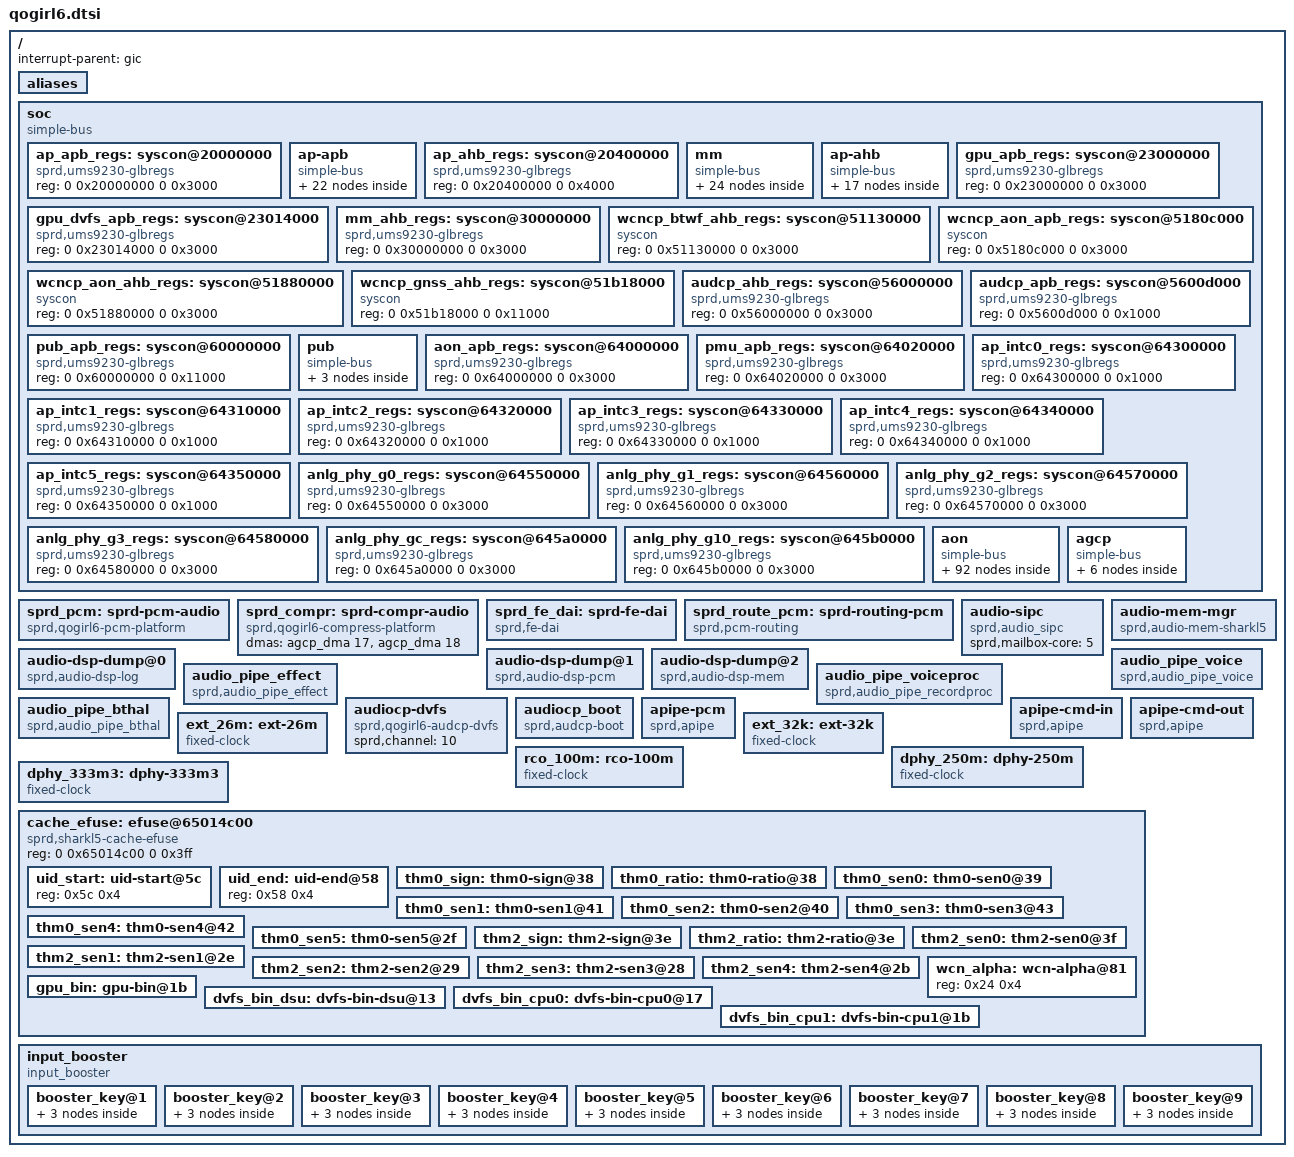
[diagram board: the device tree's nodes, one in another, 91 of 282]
// SPDX-License-Identifier: GPL-2.0-only
/*
 * Unisoc Qogirl6 platform DTS file
 *
 * Copyright (C) 2020, Unisoc Inc.
 */

#include <dt-bindings/clock/sprd,ums9230-clk.h>
#include <dt-bindings/soc/sprd,qogirl6-regs.h>
#include <dt-bindings/soc/sprd,qogirl6-mask.h>
#include <dt-bindings/debug/busmonitor/busmonitor.h>
#include <dt-bindings/debug/dmc_mpu/qogirl6_dmc_mpu.h>

/ {
	interrupt-parent = <&gic>;
	#address-cells = <2>;
	#size-cells = <2>;

	aliases {
		i2c0 = &i2c0;
		i2c1 = &i2c1;
		i2c2 = &i2c2;
		i2c3 = &i2c3;
		i2c4 = &i2c4;
		i2c5 = &i2c5;
		i2c6 = &i2c6;
		i2c7 = &aon_i2c0;
		spi0 = &spi0;
		spi1 = &spi1;
		spi2 = &spi2;
		spi3 = &spi3;
		spi4 = &adi_bus;
		thm-sensor15 = &cluster0_sensor;
		thm-sensor16 = &cluster1_sensor;
		thm-sensor17 = &soc_sensor;
	};

	soc: soc {
		compatible = "simple-bus";
		#address-cells = <2>;
		#size-cells = <2>;
		ranges;

		ap_apb_regs: syscon@20000000 {
			compatible = "sprd,ums9230-glbregs", "syscon";
			#syscon-cells = <2>;
			reg = <0 0x20000000 0 0x3000>;
		};

		ap-apb {
			compatible = "simple-bus";
			#address-cells = <2>;
			#size-cells = <2>;
			ranges;

			uart0: serial@0x200a0000  {
				compatible = "sprd,ums9230-uart",
					     "sprd,sc9836-uart";
				reg = <0 0x200a0000 0 0x100>;
				interrupts = <GIC_SPI 2 IRQ_TYPE_LEVEL_HIGH>;
				clock-names = "enable", "uart", "source";
				clocks = <&apapb_gate CLK_UART0_EB>,
					<&ap_clk CLK_AP_UART0>, <&ext_26m>;
				status = "disabled";
			};

			uart1: serial@0x200b0000 {
				compatible = "sprd,ums9230-uart",
					     "sprd,sc9836-uart";
				reg = <0 0x200b0000 0 0x100>;
				interrupts = <GIC_SPI 3 IRQ_TYPE_LEVEL_HIGH>;
				clock-names = "enable", "uart", "source";
				clocks = <&apapb_gate CLK_UART1_EB>,
					<&ap_clk CLK_AP_UART1>, <&ext_26m>;
				status = "disabled";
			};

			uart2: serial@0x200c0000 {
				compatible = "sprd,ums9230-uart",
						"sprd,sc9836-uart";
				reg = <0 0x200c0000 0 0x100>;
				interrupts = <GIC_SPI 4 IRQ_TYPE_LEVEL_HIGH>;
				clock-names = "enable", "uart", "source";
				clocks = <&apapb_gate CLK_UART2_EB>,
					<&ap_clk CLK_AP_UART2>, <&ext_26m>;
				status = "disabled";
			};

			i2c0: i2c@0x200d0000 {
				compatible = "sprd,qogirl6-i2c";
				reg = <0 0x200d0000 0 0x100>;
				interrupts = <GIC_SPI 11 IRQ_TYPE_LEVEL_HIGH>;
				clock-frequency = <400000>;
				#address-cells = <1>;
				#size-cells = <0>;
				status = "disabled";
				syscon-names = "i2c_rst";
				syscons =
					<&ap_apb_regs REG_AP_APB_APB_RST MASK_AP_APB_I2C0_SOFT_RST>;
			};

			i2c1: i2c@0x200e0000 {
				compatible = "sprd,qogirl6-i2c";
				reg = <0 0x200e0000 0 0x100>;
				interrupts = <GIC_SPI 12 IRQ_TYPE_LEVEL_HIGH>;
				clock-frequency = <400000>;
				#address-cells = <1>;
				#size-cells = <0>;
				status = "disabled";
				syscon-names = "i2c_rst";
				syscons =
					<&ap_apb_regs REG_AP_APB_APB_RST MASK_AP_APB_I2C1_SOFT_RST>;
			};

			i2c2: i2c@0x200f0000 {
				compatible = "sprd,qogirl6-i2c";
				reg = <0 0x200f0000 0 0x100>;
				interrupts = <GIC_SPI 13 IRQ_TYPE_LEVEL_HIGH>;
				clock-frequency = <400000>;
				#address-cells = <1>;
				#size-cells = <0>;
				status = "disabled";
				syscon-names = "i2c_rst";
				syscons =
					<&ap_apb_regs REG_AP_APB_APB_RST MASK_AP_APB_I2C2_SOFT_RST>;
			};

			i2c3: i2c@0x20100000 {
				compatible = "sprd,qogirl6-i2c";
				reg = <0 0x20100000 0 0x100>;
				interrupts = <GIC_SPI 14 IRQ_TYPE_LEVEL_HIGH>;
				clock-frequency = <400000>;
				#address-cells = <1>;
				#size-cells = <0>;
				status = "disabled";
				syscon-names = "i2c_rst";
				syscons =
					<&ap_apb_regs REG_AP_APB_APB_RST MASK_AP_APB_I2C3_SOFT_RST>;
			};

			i2c4: i2c@0x20110000 {
				compatible = "sprd,qogirl6-i2c";
				reg = <0 0x20110000 0 0x100>;
				interrupts = <GIC_SPI 15 IRQ_TYPE_LEVEL_HIGH>;
				clock-frequency = <400000>;
				#address-cells = <1>;
				#size-cells = <0>;
				status = "disabled";
				syscon-names = "i2c_rst";
				syscons =
					<&ap_apb_regs REG_AP_APB_APB_RST MASK_AP_APB_I2C4_SOFT_RST>;
			};

			i2s0: i2s@0x20160000 {
				compatible = "sprd,i2s";
				reg = <0 0x20160000 0 0x1000>;
				sprd,dai_name = "i2s_bt_sco0";
				sprd,hw_port = <0>;
				sprd,syscon-ap-apb = <&ap_apb_regs>;
				#sound-dai-cells = <0>;
				status = "disable";
				clock-names = "clk_iis0";
				clocks = <&ap_clk CLK_AP_IIS0>;
			};

			i2c5: i2c@0x20210000 {
				compatible = "sprd,qogirl6-i2c";
				reg = <0 0x20210000 0 0x100>;
				interrupts = <GIC_SPI 35 IRQ_TYPE_LEVEL_HIGH>;
				clock-frequency = <400000>;
				#address-cells = <1>;
				#size-cells = <0>;
				status = "disabled";
				syscon-names = "i2c_rst";
				syscons =
					<&ap_apb_regs REG_AP_APB_APB_RST MASK_AP_APB_I2C5_SOFT_RST>;
			};

			i2c6: i2c@0x20220000 {
				compatible = "sprd,qogirl6-i2c";
				reg = <0 0x20220000 0 0x100>;
				interrupts = <GIC_SPI 36 IRQ_TYPE_LEVEL_HIGH>;
				clock-frequency = <400000>;
				#address-cells = <1>;
				#size-cells = <0>;
				status = "disabled";
				syscon-names = "i2c_rst";
				syscons =
					<&ap_apb_regs REG_AP_APB_APB_RST MASK_AP_APB_I2C6_SOFT_RST>;
			};

			spi0: spi@20120000{
				compatible = "sprd,sc9860-spi", "sprd,sharkl5-spi";
				reg = <0 0x20120000 0 0x1000>;
				interrupts = <GIC_SPI 5 IRQ_TYPE_LEVEL_HIGH>;
				#address-cells = <1>;
				#size-cells = <0>;
				status = "disabled";
			};

			spi1: spi@20130000{
				compatible = "sprd,sc9860-spi", "sprd,sharkl5-spi";
				reg = <0 0x20130000 0 0x1000>;
				interrupts = <GIC_SPI 6 IRQ_TYPE_LEVEL_HIGH>;
				#address-cells = <1>;
				#size-cells = <0>;
				status = "disabled";
			};

			spi2: spi@20140000{
				compatible = "sprd,sc9860-spi", "sprd,sharkl5-spi";
				reg = <0 0x20140000 0 0x1000>;
				interrupts = <GIC_SPI 7 IRQ_TYPE_LEVEL_HIGH>;
				#address-cells = <1>;
				#size-cells = <0>;
				status = "disabled";
			};

			spi3: spi@20150000{
				compatible = "sprd,sc9860-spi", "sprd,sharkl5-spi";
				reg = <0 0x20150000 0 0x1000>;
				interrupts = <GIC_SPI 8 IRQ_TYPE_LEVEL_HIGH>;
				#address-cells = <1>;
				#size-cells = <0>;
				status = "disabled";
			};

			sdio3: sdio@201d0000 {
				compatible = "sprd,sdhc-r11p1";
				reg = <0 0x201d0000 0 0x1000>;
				interrupts = <GIC_SPI 10 IRQ_TYPE_LEVEL_HIGH>;
				status = "disabled";
			};

			sdio0: sdio@201a0000 {
				compatible = "sprd,sdhc-r11p1";
				reg = <0 0x201a0000 0 0x1000>;
				interrupts = <GIC_SPI 19 IRQ_TYPE_LEVEL_HIGH>;
				status = "disabled";
				syscons = <&aon_apb_regs REG_AON_APB_AP_SDIO0_PHY_CTRL MASK_AON_APB_AP_SDIO0_CARD_PRESENT_32K>,
					  <&aon_apb_regs REG_AON_APB_AP_SDIO0_PHY_CTRL MASK_AON_APB_AP_SDIO0_CARD_PROTECT_32K>,
					  <&aon_apb_regs REG_AON_APB_AP_SDIO0_PHY_CTRL MASK_AON_APB_AP_SDIO0_CARDDET_DBNC_EN_32K>,
					  <&aon_apb_regs REG_AON_APB_AP_SDIO0_PHY_CTRL MASK_AON_APB_AP_SDIO0_CARDDET_DBNC_THD_32K>;
				syscon-names = "sd_detect_pol",
					       "sd_hotplug_protect_en",
					       "sd_hotplug_debounce_en",
					       "sd_hotplug_debounce_cn";
			};

			sdio1: sdio@201b0000 {
				compatible = "sprd,sdhc-r11p1";
				reg = <0 0x201b0000 0 0x1000>;
				interrupts = <GIC_SPI 20 IRQ_TYPE_LEVEL_HIGH>;
				status = "disabled";
			};

			sdio2: sdio@201c0000 {
				compatible = "sprd,sdhc-r11p1";
				reg = <0 0x201c0000 0 0x1000>;
				interrupts = <GIC_SPI 21 IRQ_TYPE_LEVEL_HIGH>;
				status = "disabled";
			};

			apsys_dvfs: apsys-dvfs@71700000 {
				compatible = "sprd,hwdvfs-apsys-qogirl6";
				reg = <0x0 0x20014000 0x0 0x15c>;

				sprd,ap-dvfs-up-window = <0x40>;
				sprd,ap-dvfs-down-window = <0x80>;
			};

			crypto_engine_rng: rng@201e0000 {
				compatible = "sprd,sprd-trng";
				reg = <0x0 0x201e0000 0x0 0x10000>;
				clock-names = "ce-pub-eb", "ap-ce-clk",
							  "source";
				clocks = <&apapb_gate CLK_CE_PUB_EB>,
						 <&ap_clk CLK_AP_CE>,
						 <&pll1 CLK_TWPLL_256M>;
			};

			ufs: ufs@20200000 {
				compatible  = "sprd,ufshc";
				vcc-supply = <&vddemmccore>;
				vcc-fixed-regulator;
				clock-names = "ufs_reg_eb", "ufs_en",
					      "ufs_pclk", "ufs_pclk_source",
					      "ufs_hclk", "ufs_hclk_source";
				clocks = <&apapb_gate CLK_UFS_REG_EB>,
					 <&apapb_gate CLK_UFS_EB>,
					 <&ap_clk CLK_UFS_PCK>,
					 <&pll1 CLK_TWPLL_256M>,
					 <&ap_clk CLK_UFS_HCK>,
					 <&pll1 CLK_TWPLL_256M>;
				freq-table-hz = <0 0>,
						<0 0>,
						<0 0>,
						<0 0>,
						<0 0>,
						<0 0>;
				/*#clock-cells = <1>;*/
				reg = <0 0x20200000 0 0x10000>,
				      <0 0x20400000 0 0x10000>,
				      <0 0x64560000 0 0x10000>;
				reg-names = "ufshci_reg",
					    "ap_ahb_reg",
					    "ufs_analog_reg";
				syscons =
					<&aon_apb_regs REG_AON_APB_APB_EB1 (MASK_AON_APB_PIN_EB | MASK_AON_APB_ANA_EB)>,
					<&ap_ahb_regs REG_AP_AHB_UFS_CLK_CTRL MASK_AP_AHB_CG_CFGCLK_SW>,
					<&ap_apb_regs REG_AP_APB_APB_RST MASK_AP_APB_UFS_REG_SOFT_RST>,
					<&ap_apb_regs REG_AP_APB_APB_EB1 MASK_AP_APB_UFS_EB>,
					<&ap_ahb_regs REG_AP_AHB_MPHY_CB_CHANNEL_0 MASK_AP_AHB_REFCLKON>,
					<&ap_ahb_regs REG_AP_AHB_UFS_LP_CTRL_1 (MASK_AP_AHB_UFS_FORCE_LP_RESET_N |
								MASK_AP_AHB_UFS_FORCE_LP_PWR_READY | MASK_AP_AHB_UFS_SEL_LP_PWR_READY |
								MASK_AP_AHB_UFS_SEL_LP_RESET_N | MASK_AP_AHB_UFS_SEL_LP_ISOL_EN )>,
					<&ap_ahb_regs REG_AP_AHB_UFS_LP_CTRL_1 MASK_AP_AHB_UFS_FORCE_LP_ISOL_EN>,
					<&ap_ahb_regs REG_AP_AHB_UFS_LP_CTRL_1 (MASK_AP_AHB_UFS_CG_LP_PWR_READY_BYPASS | MASK_AP_AHB_UFS_FORCE_LP_RESET_N)>,
					<&ap_ahb_regs REG_AP_AHB_MPHY_CB_CHANNEL_0 (MASK_AP_AHB_CB_RESET | MASK_AP_AHB_CB_CFGCLK)>;
				syscon-names =
					"aon_apb_ufs_en",
					"ap_ahb_ufs_clk",
					"ap_apb_ufs_rst",
					"ap_apb_ufs_en",
					"ufs_refclk_on",
					"ahb_ufs_lp",
					"ahb_ufs_force_isol",
					"ahb_ufs_lp_1",
					"ahb_ufs_cb";
				interrupts = <GIC_SPI 147 IRQ_TYPE_LEVEL_HIGH>;
			};
		};

		ap_ahb_regs: syscon@20400000 {
			compatible = "sprd,ums9230-glbregs", "syscon";
			#syscon-cells = <2>;
			reg = <0 0x20400000 0 0x4000>;
		};

		mm {
			compatible = "simple-bus";
			#address-cells = <2>;
			#size-cells = <2>;
			ranges;

			mm_domain: mm_domain {
				compatible = "sprd,mm-domain";

				syscon-names = "force_shutdown",
						"shutdown_en",
						"power_state",
						"aon_apb_mm_eb";
				syscons = <&pmu_apb_regs
					REG_PMU_APB_PD_MM_CFG_0
					MASK_PMU_APB_PD_MM_FORCE_SHUTDOWN>,
					<&pmu_apb_regs
					REG_PMU_APB_PD_MM_CFG_0
					MASK_PMU_APB_PD_MM_AUTO_SHUTDOWN_EN>,
					<&pmu_apb_regs
					REG_PMU_APB_PWR_STATUS_DBG_6
					MASK_PMU_APB_PD_MM_STATE>,
					<&aon_apb_regs
					REG_AON_APB_APB_EB0
					MASK_AON_APB_MM_EB>;

				clock-names = "clk_mm_eb",
					"clk_mm_ahb_eb",
					"clk_mm_ahb",
					"clk_mm_ahb_parent",
					"clk_mm_mtx",
					"clk_mm_mtx_parent",
					"clk_isppll";
				clocks = <&aonapb_gate CLK_MM_EB>,
					<&mm_gate CLK_MM_CKG_EB>,
					<&mm_clk CLK_MM_AHB>,
					<&pll1 CLK_TWPLL_153M6>,
					<&mm_clk CLK_MM_MTX>,
					<&pll1 CLK_TWPLL_512M>,
					<&pll1 CLK_ISPPLL_468M>;
				mm_qos_threshold = <&mm_qos_threshold>;
			};

			vsp: video-codec@32000000 {
				compatible = "sprd,qogirl6-vsp";
				reg = <0 0x32000000 0 0xc000>;
				interrupts = <GIC_SPI 34 IRQ_TYPE_LEVEL_HIGH>;

				syscons =
					<&ap_ahb_regs REG_AP_AHB_AHB_RST
					(MASK_AP_AHB_VSP_SOFT_RST |
					MASK_AP_AHB_VSP_GLOBAL_SOFT_RST)>,
					<&pmu_apb_regs
					REG_PMU_APB_PD_AP_VSP_CFG_0
					MASK_PMU_APB_PD_AP_VSP_FORCE_SHUTDOWN>,
					<&pmu_apb_regs
					REG_PMU_APB_PD_AP_VSP_CFG_0
					MASK_PMU_APB_PD_AP_VSP_AUTO_SHUTDOWN_EN>,
					<&pmu_apb_regs
					REG_PMU_APB_PWR_STATUS_DBG_9
					MASK_PMU_APB_PD_AP_VSP_STATE>,
					<&aon_apb_regs
					REG_AON_APB_APB_EB1
					MASK_AON_APB_AP_SYST_EB>;
				syscon-names = "reset",
					"pmu_vsp_force_shutdown",
					"pmu_vsp_auto_shutdown",
					"pmu_pwr_status",
					"vsp_domain_eb";

				iommus = <&iommu_vsp>;
				status = "okay";
			};

			iommu_vsp: iommu@32000000 {
				compatible = "sprd,iommuvau-vsp";
				reg = <0x0 0x32000000 0x0 0x80>;
				sprd,iova-base = <0x20000000>;
				sprd,iova-size = <0x10000000>;
				reg_name = "mmu_reg";
				status = "disable";
				#iommu-cells = <0>;
			};

			jpg: jpg-codec@36000000{
				compatible = "sprd,qogirl6-jpg";
				reg = <0 0x36000000 0 0xc000>;
				interrupts = <GIC_SPI 42 IRQ_TYPE_LEVEL_HIGH>;

				syscons = <&mm_ahb_regs REG_MM_AHB_AHB_RST
					MASK_MM_AHB_JPG_SOFT_RST_MASK>,
					<&aon_apb_regs
					REG_AON_APB_APB_EB0
					MASK_AON_APB_MM_EB>;
				syscon-names = "reset",
					"aon_apb_eb";
					iommus = <&iommu_jpg>;
					jpg_qos = <&jpg_qos>;
				status = "disabled";
			};

			iommu_jpg: iommu@36000300 {
				compatible = "sprd,iommuvau-jpg";
				reg = <0x0 0x36000300 0x0 0x80>;
				sprd,iova-base = <0x60000000>;
				sprd,iova-size = <0x10000000>;
				reg_name = "mmu_reg";
				status = "disabled";
				#iommu-cells = <0>;
			};

			mipi_csi_phy0: mipi-csi-phy0 {
				compatible = "sprd,mipi-csi-phy";
				sprd,phyid = <0>;
				sprd,phyname = "4lane";
				status = "disabled";
			};

			mipi_csi_phy1: mipi-csi-phy1 {
				compatible = "sprd,mipi-csi-phy";
				sprd,phyid = <1>;
				sprd,phyname = "2p2";
				status = "disabled";
			};

			mipi_csi_phy1_m: mipi-csi-phy1-m {
				compatible = "sprd,mipi-csi-phy";
				sprd,phyid = <3>;
				sprd,phyname = "2p2_m";
				status = "disabled";
			};

			mipi_csi_phy1_s: mipi-csi-phy1-s {
				compatible = "sprd,mipi-csi-phy";
				sprd,phyid = <4>;
				sprd,phyname = "2p2_s";
				status = "disabled";
			};

			mipi_csi_phy2: mipi-csi-phy2 {
				compatible = "sprd,mipi-csi-phy";
				sprd,phyid = <2>;
				sprd,phyname = "2p2ro";
				status = "disabled";
			};
			mipi_csi_phy2_m: mipi-csi-phy2-m {
				compatible = "sprd,mipi-csi-phy";
				sprd,phyid = <5>;
				sprd,phyname = "2p2ro_m";
				status = "disabled";
			};

			mipi_csi_phy2_s: mipi-csi-phy2-s {
				compatible = "sprd,mipi-csi-phy";
				sprd,phyid = <6>;
				sprd,phyname = "2p2ro_s";
				status = "disabled";
			};
			csi0: csi00@3e200000 {
				compatible = "sprd,csi-controller";
				reg = <0 0x3e200000 0 0x1000>;
				interrupts = <GIC_SPI 45 IRQ_TYPE_LEVEL_HIGH>,
					<GIC_SPI 46 IRQ_TYPE_LEVEL_HIGH>,
					<GIC_SPI 47 IRQ_TYPE_LEVEL_HIGH>,
					<GIC_SPI 48 IRQ_TYPE_LEVEL_HIGH>;
				clock-names = "clk_mipi_csi_gate_eb",
					"clk_csi_eb",
					"mipi_csi_src_eb";
				clocks = <&mm_gate CLK_MM_MIPI_CSI0_EB>,
					<&mm_gate CLK_MM_CSI0_EB>,
					<&mm_clk CLK_MIPI_CSI0>;
				sprd,aon-apb-syscon = <&aon_apb_regs>;
				sprd,cam-ahb-syscon = <&mm_ahb_regs>;
				sprd,anlg_phy_g10_controller = <&anlg_phy_g10_regs>;
				sprd,csi-id = <0>;
				sprd,dcam-id = <0>;
				sprd,ip-version = <0x200>;
				status = "okay";
			};

			csi1: csi01@3e300000 {
				compatible = "sprd,csi-controller";
				reg = <0 0x3e300000 0 0x1000>;
				interrupts = <GIC_SPI 49 IRQ_TYPE_LEVEL_HIGH>,
					<GIC_SPI 50 IRQ_TYPE_LEVEL_HIGH>,
					<GIC_SPI 51 IRQ_TYPE_LEVEL_HIGH>,
					<GIC_SPI 52 IRQ_TYPE_LEVEL_HIGH>;
				clock-names = "clk_mipi_csi_gate_eb",
					"clk_csi_eb",
					"mipi_csi_src_eb";
				clocks = <&mm_gate CLK_MM_MIPI_CSI1_EB>,
					<&mm_gate CLK_MM_CSI1_EB>,
					<&mm_clk CLK_MIPI_CSI1>;
				sprd,aon-apb-syscon = <&aon_apb_regs>;
				sprd,cam-ahb-syscon = <&mm_ahb_regs>;
				sprd,anlg_phy_g10_controller = <&anlg_phy_g10_regs>;
				sprd,csi-id = <1>;
				sprd,dcam-id = <1>;
				sprd,ip-version = <0x200>;
				status = "okay";
			};

			csi2: csi02@3e400000 {
				compatible = "sprd,csi-controller";
				reg = <0 0x3e400000 0 0x1000>;
				interrupts = <GIC_SPI 53 IRQ_TYPE_LEVEL_HIGH>,
					<GIC_SPI 54 IRQ_TYPE_LEVEL_HIGH>,
					<GIC_SPI 55 IRQ_TYPE_LEVEL_HIGH>,
					<GIC_SPI 56 IRQ_TYPE_LEVEL_HIGH>;
				clock-names = "clk_mipi_csi_gate_eb",
					"clk_csi_eb",
					"mipi_csi_src_eb";
				clocks = <&mm_gate CLK_MM_MIPI_CSI2_EB>,
					<&mm_gate CLK_MM_CSI2_EB>,
					<&mm_clk CLK_MIPI_CSI2>;
				sprd,aon-apb-syscon = <&aon_apb_regs>;
				sprd,cam-ahb-syscon = <&mm_ahb_regs>;
				sprd,anlg_phy_g10_controller = <&anlg_phy_g10_regs>;
				sprd,csi-id = <2>;
				sprd,dcam-id = <2>;
				sprd,ip-version = <0x200>;
				status = "okay";
			};
			isp: isp@3a000000 {
				compatible = "sprd,isp";
				reg = <0 0x3a000000 0 0x100000>;
				interrupts = <GIC_SPI 43 IRQ_TYPE_LEVEL_HIGH>,
					<GIC_SPI 44 IRQ_TYPE_LEVEL_HIGH>;
				interrupts_name = "ispch0", "ispch1";
				clock-names = "isp_eb",
					"isp_axi_eb", /* no need read, TBC */
					"isp_clk",
					"isp_clk_256m",
					"isp_clk_307m2",
					"isp_clk_384m",
					"isp_clk_468m",
					"isp_clk_512m",
					"isp_clk_parent";
				clocks = <&mm_gate CLK_MM_ISP_EB>,
					<&mm_gate CLK_ISP_AHB_EB>,
					<&mm_clk CLK_ISP>,
					<&pll1 CLK_TWPLL_256M>,
					<&pll1 CLK_TWPLL_307M2>,
					<&pll1 CLK_TWPLL_384M>,
					<&pll1 CLK_ISPPLL_468M>,
					<&pll1 CLK_TWPLL_512M>,
					<&pll1 CLK_TWPLL_512M>;
				syscons = <&mm_ahb_regs
					REG_MM_AHB_AHB_RST
					MASK_MM_AHB_ISP_SOFT_RST>,
					<&mm_ahb_regs
					REG_MM_AHB_AHB_RST
					MASK_MM_AHB_ISP_AHB_SOFT_RST>,
					<&mm_ahb_regs
					REG_MM_AHB_AHB_RST
					MASK_MM_AHB_ISP_VAU_SOFT_RST>,
					<&mm_ahb_regs
					REG_MM_AHB_AHB_EB
					MASK_MM_AHB_ISP_EB>;
				sprd,cam-ahb-syscon = <&mm_ahb_regs>;
				syscon-names = "reset",
					"isp_ahb_reset",
					"isp_vau_reset",
					"isp_enable";
				sprd,isp-count = <1>;
				iommus = <&iommu_isp>;
				isp_qos = <&isp_qos>;
				status = "okay";
			};
			iommu_isp: iommu@3a000000 {
				compatible = "sprd,iommuvau-isp";
				reg = <0x0 0x3a0ff000 0x0 0x80>;
				sprd,iova-base = <0x40000000>;
				sprd,iova-size = <0x20000000>;
				reg_name = "mmu_reg";
				status = "okay";
				#iommu-cells = <0>;
			};
			dcam: dcam@3e000000 {
				compatible = "sprd,qogirl6-cam";
				reg = <0 0x3e000000 0 0x1000>,
					<0 0x3e001000 0 0x1000>,
					<0 0x3e002000 0 0x1000>,
					<0 0x3e003000 0 0x1000>;
				reg-names = "dcam0_reg",
						"dcam1_reg",
						"dcam2_reg",
						"axi_ctrl_reg";
				interrupts = <GIC_SPI 57 IRQ_TYPE_LEVEL_HIGH>,
					<GIC_SPI 58 IRQ_TYPE_LEVEL_HIGH>,
					<GIC_SPI 59 IRQ_TYPE_LEVEL_HIGH>;
				interrupt-names = "dcam0",
							"dcam1",
							"dcam2";
				clock-names = "dcam_eb",
					"dcam_clk",
					"dcam_clk_192m",
					"dcam_clk_256m",
					"dcam_clk_307m2",
					"dcam_clk_384m",
					"dcam_clk_468m",
					"dcam_clk_parent";
				clocks = <&mm_gate CLK_MM_DCAM_EB>,
					<&mm_clk CLK_DCAM_IF>,
					<&pll1 CLK_TWPLL_192M>,
					<&pll1 CLK_TWPLL_256M>,
					<&pll1 CLK_TWPLL_307M2>,
					<&pll1 CLK_TWPLL_384M>,
					<&pll1 CLK_ISPPLL_468M>,
					<&pll1 CLK_ISPPLL_468M>;
				syscons = <&mm_ahb_regs REG_MM_AHB_AHB_RST
					MASK_MM_AHB_DCAM_ALL_SOFT_RST>,
					<&mm_ahb_regs REG_MM_AHB_AHB_RST
					MASK_MM_AHB_DCAM0_SOFT_RST>,
					<&mm_ahb_regs REG_MM_AHB_AHB_RST
					MASK_MM_AHB_DCAM1_SOFT_RST>,
					<&mm_ahb_regs REG_MM_AHB_AHB_RST
					MASK_MM_AHB_DCAM2_SOFT_RST>;
				syscon-names = "dcam_all_reset",
						"dcam0_reset",
						"dcam1_reset",
						"dcam2_reset";
				sprd,cam-ahb-syscon = <&mm_ahb_regs>;
				sprd,isp = <&isp>;
				sprd,dcam-count = <3>;
				sprd,dcam-superzoom = <2>;
				sprd,project-id = <5>;
				iommus = <&iommu_dcam>;
				dcam_qos = <&dcam_qos>;
				status = "okay";
			};
			iommu_dcam: iommu@3e000000 {
				compatible = "sprd,iommuvau-dcam";
				reg = <0x0 0x3e00f000 0x0 0x80>;
				sprd,iova-base = <0x40000000>;
				sprd,iova-size = <0x40000000>;
				reg_name = "mmu_reg";
				status = "okay";
				#iommu-cells = <0>;
			};
			fd: fd@3C000000 {
				compatible = "sprd,fd";
				reg = <0 0x3C000000 0 0x100000>;
				interrupts = <GIC_SPI 40 IRQ_TYPE_LEVEL_HIGH>;
				interrupts_name = "fdraw";
				clock-names = "fd_eb",
					"fd_axi_eb", /* no need read, TBC */
					"fd_clk",
					"fd_clk_parent";
				clocks = <&mm_gate CLK_MM_FD_EB>,
					<&mm_gate CLK_MM_ISP_EB>,
					<&mm_clk CLK_FD>,
					<&pll1 CLK_TWPLL_384M>;
				syscons = <&mm_ahb_regs REG_MM_AHB_AHB_EB
					MASK_MM_AHB_FD_EB>,
					<&mm_ahb_regs REG_MM_AHB_AHB_RST
					MASK_MM_AHB_FD_SOFT_RST>,
					<&mm_ahb_regs REG_MM_AHB_AHB_RST
					MASK_MM_AHB_FD_SOFT_RST_MASK>,
					<&mm_ahb_regs REG_MM_AHB_MM_LPC_CTRL_FD
					MASK_MM_AHB_LP_EB_FD>,
					<&mm_ahb_regs REG_MM_AHB_AHB_EB
					MASK_MM_AHB_DVFS_EB>;
				syscon-names = "fd_eb", "fd_rst", "fd_save_rst",
					"fd_lpc", "fd_dvfs_eb";
				iommus = <&iommu_fd>;
				fd_qos = <&fd_qos>;
				status = "okay";
			};
			iommu_fd: iommu@3C000000 {
				compatible = "sprd,iommuvau-fd";
				reg = <0 0x3C000110 0 0x80>;
				sprd,iova-base = <0x40000000>;
				sprd,iova-size = <0x10000000>;
				reg_name = "mmu_reg";
				status = "okay";
				#iommu-cells = <0>;
			};
			cpp: cpp@38000000 {
				compatible = "sprd,cpp";
				reg = <0 0x38000000 0 0x1000>;
				interrupts = <GIC_SPI 41 IRQ_TYPE_LEVEL_HIGH>;
				clock-names = "cpp_eb",
					"cpp_axi_eb", /* no need read, TBC */
					"cpp_clk",
					"cpp_clk_parent";
				clocks = <&mm_gate CLK_MM_CPP_EB>,
					<&mm_gate CLK_MM_ISP_EB>,
					<&mm_clk CLK_CPP>,
					<&pll1 CLK_TWPLL_384M>;
				sprd,cam-ahb-syscon = <&mm_ahb_regs>;
				iommus = <&iommu_cpp>;
				cpp_qos = <&cpp_qos>;
				status = "okay";
			};

			iommu_cpp: iommu@38000200 {
				compatible = "sprd,iommuvau-cpp";
				reg = <0x0 0x38000200 0x0 0x80>;
				sprd,iova-base = <0x40000000>;
				sprd,iova-size = <0x20000000>;
				reg_name = "mmu_reg";
				status = "okay";
				#iommu-cells = <0>;
			};

			gpu: gpu@23100000 {
				compatible = "sprd,mali-natt";
				reg = <0x0 0x23100000 0x0 0x100000>;
				gpu-supply = <&vddgpu>;
				system-coherency = <31>;
				topdvfs-controller = <&topdvfs_controller>;
				sprd,gpu-apb-syscon = <&gpu_apb_regs>;
				sprd,gpu-dvfs-apb-syscon = <&gpu_dvfs_apb_regs>;
				syscons = <&pmu_apb_regs
					REG_PMU_APB_PD_GPU_TOP_CFG_0
					MASK_PMU_APB_PD_GPU_TOP_FORCE_SHUTDOWN>,
				<&pmu_apb_regs
					REG_PMU_APB_PWR_STATUS_DBG_4
					MASK_PMU_APB_PD_GPU_C0_STATE>,
				<&gpu_apb_regs
					REG_GPU_APB_GONDUL_PDC_CONTROL_STACK0
					MASK_GPU_APB_CUR_ST_ST0>,
				<&aon_apb_regs
					REG_AON_APB_RF_BOND_OPT0
					MASK_AON_APB_RF_BOND_OPTION0>;

				syscon-names = "top-force-shutdown",
						"gpu_core0_state",
						"cur_st_st0",
						"mem_repaired_flag";

				interrupts = <GIC_SPI 60 IRQ_TYPE_LEVEL_HIGH>,
					<GIC_SPI 60 IRQ_TYPE_LEVEL_HIGH>,
					<GIC_SPI 60 IRQ_TYPE_LEVEL_HIGH>;
				interrupt-names = "JOB",
					"MMU",
					"GPU";

				nvmem-cells = <&gpu_bin>;
				nvmem-cell-names = "gpu_bin";

				operating-points = <
					/* kHz    uV */
					384000    700000
					512000    750000
					614400    750000
					768000    800000
					850000    800000
					>;

				sprd,dvfs-lists = <
					/* kHz   uV      idx div */
					384000  700000    4    1
					512000  750000    5    1
					614400  750000    6    1
					768000  800000    7    1
					850000  800000    8    1
					>;

				/*sprd,qos = <&gpu_qos>;*/
				sprd,dvfs-default = <0>;
				sprd,dvfs-scene-extreme = <3>;
				sprd,dvfs-scene-high = <2>;
				sprd,dvfs-scene-medium = <1>;
				sprd,dvfs-scene-low = <0>;
				sprd,dvfs-range-max = <4>;
				sprd,dvfs-range-min = <0>;
			};
		};

		ap-ahb {
			compatible = "simple-bus";
			#address-cells = <2>;
			#size-cells = <2>;
			ranges;

			ap_dma: dma-controller@20410000 {
				compatible = "sprd,qogirl6-dma";
				reg = <0 0x20410000 0 0x4000>;
				interrupts = <GIC_SPI 24 IRQ_TYPE_LEVEL_HIGH>;
				#dma-cells = <1>;
				#dma-channels = <28>;
				clock-names = "enable";
				clocks = <&apahb_gate CLK_DMA_PUB_EB>;
			};

			dpu: dpu@31000000 {
				compatible = "sprd,display-processor";
				reg = <0x0 0x31000000 0x0 0x1000>,
				      <0x0 0x31001000 0x0 0x1000>;
				syscons = <&ap_ahb_regs 0x0004 0x2>,
					<&ap_ahb_regs 0x0004 0x4000>;
				syscon-names = "disp_reset", "iommu_reset";
				interrupts = <GIC_SPI 27 IRQ_TYPE_LEVEL_HIGH>;
				status = "disabled";
				iommus = <&iommu_dispc>;

				dma-coherent;

				sprd,ip = "dpu-r5p0";
				sprd,soc = "qogirl6";

				dpu_port: port {
					dpu_out: endpoint {
						remote-endpoint = <&dsi_in>;
					};
				};
			};

			gsp_core0: gsp@31000000 {
				compatible = "sprd,gsp-core";
				reg = <0 0x31000000 0 0x2000>;
				core-id = <0>;
				kcfg-num = <16>;
				interrupts = <GIC_SPI 26 IRQ_TYPE_LEVEL_HIGH>;
				iommus = <&iommu_dispc>;
			};

			iommu_dispc: iommu@31000000 {
				compatible = "sprd,iommuvau-dispc";
				reg = <0x0 0x31000800 0x0 0x80>;
				sprd,iova-base = <0x30000000>;
				sprd,iova-size = <0x10000000>;
				reg_name = "mmu_reg";
				status = "disabled";
				#iommu-cells = <0>;
			};

			dsi: dsi@31100000 {
				compatible = "sprd,dsi-host";
				reg = <0x0 0x31100000 0x0 0x1000>;
				syscons = <&ap_ahb_regs 0x0004 0x1>;
				syscon-names = "reset";
				interrupts = <GIC_SPI 30 IRQ_TYPE_LEVEL_HIGH>,
					<GIC_SPI 31 IRQ_TYPE_LEVEL_HIGH>;
				status = "disabled";

				sprd,ip = "sprd,dsi-ctrl", "r3p1";
				sprd,soc = "qogirl6";

				ports {
					#address-cells = <1>;
					#size-cells = <0>;

					port@0 {
						reg = <0>;
						dsi_out: endpoint {
							remote-endpoint = <&dphy_in>;
						};
					};

					port@1 {
						reg = <1>;
						dsi_in: endpoint {
							remote-endpoint = <&dpu_out>;
						};
					};
				};
			};

			dphy: dphy {
				compatible = "sprd,dsi-phy";
				#address-cells = <1>;
				#size-cells = <0>;
				reg = <0x0 0x31100000 0x0 0x1000>;
				syscons = <&ap_ahb_regs 0x0040 (0x2 | 0x1)>,
					<&pmu_apb_regs 0x009C 0x0020>;
				syscon-names = "enable", "power";
				status = "disabled";

				sprd,ip = "sprd,megacores-sharkl5";
				sprd,soc = "qogirl6";
				sprd,mipi-drive-capability = <5>;

				/* output port */
				port@0 {
					reg = <0>;
					dphy_out: endpoint {
						remote-endpoint = <&panel_in>;
					};
				};

				/* input port*/
				port@1 {
					reg = <1>;
					dphy_in: endpoint {
						remote-endpoint = <&dsi_out>;
					};
				};
			};
		};

		gpu_apb_regs: syscon@23000000 {
			compatible = "sprd,ums9230-glbregs", "syscon";
			#syscon-cells = <2>;
			reg = <0 0x23000000 0 0x3000>;
		};

		gpu_dvfs_apb_regs: syscon@23014000 {
			compatible = "sprd,ums9230-glbregs", "syscon";
			#syscon-cells = <2>;
			reg = <0 0x23014000 0 0x3000>;
		};

		mm_ahb_regs: syscon@30000000 {
			compatible = "sprd,ums9230-glbregs", "syscon";
			#syscon-cells = <2>;
			reg = <0 0x30000000 0 0x3000>;
		};

		wcncp_btwf_ahb_regs: syscon@51130000 {
			compatible = "syscon";
			#syscon-cells = <2>;
			reg = <0 0x51130000 0 0x3000>;
		};
		wcncp_aon_apb_regs: syscon@5180c000 {
			compatible = "syscon";
			#syscon-cells = <2>;
			reg = <0 0x5180c000 0 0x3000>;
		};
		wcncp_aon_ahb_regs: syscon@51880000 {
			compatible = "syscon";
			#syscon-cells = <2>;
			reg = <0 0x51880000 0 0x3000>;
		};

		wcncp_gnss_ahb_regs: syscon@51b18000 {
			compatible = "syscon";
			#syscon-cells = <2>;
			reg = <0 0x51b18000 0 0x11000>;
		};

		audcp_ahb_regs: syscon@56000000 {
			compatible = "sprd,ums9230-glbregs", "syscon";
			#syscon-cells = <2>;
			reg = <0 0x56000000 0 0x3000>;
		};

		audcp_apb_regs: syscon@5600d000 {
			compatible = "sprd,ums9230-glbregs", "syscon";
			#syscon-cells = <2>;
			reg = <0 0x5600d000 0 0x1000>;
		};

		pub_apb_regs: syscon@60000000 {
			compatible = "sprd,ums9230-glbregs", "syscon";
			#syscon-cells = <2>;
			reg = <0 0x60000000 0 0x11000>;
		};

		pub {
			compatible = "simple-bus";
			#address-cells = <2>;
			#size-cells = <2>;
			ranges;

			dmc_mpu: dmc-mpu@60200000 {
				compatible = "sprd,qogirl6-dmc-mpu";
				reg = <0 0x60200000 0 0x10000>;
				interrupts = <GIC_SPI 111 IRQ_TYPE_LEVEL_HIGH>;
				syscon-names = "irq_clr", "irq_en";
				syscons = <&pub_apb_regs 0x32f0 0x200>,
					<&pub_apb_regs 0x32f0 0x100>;
				sprd,channel-num = <8>;
				sprd,mpu-num = <16>;
				sprd,channel-names =
					"CPU", "GPU", "DPU/DCAM","ISP",
					"AP/VSP/AON", "WTLCP", "PUBCP/AUDCP",
					"WCN", "SHARED0", "SHARED1",
					"SHARED2", "SHARED3", "SHARED4",
					"SHARED5", "SHARED6", "SHARED7";
				sprd,ranges = <0 0 0 0>, <0 0 0 0>, <0 0 0 0>,
					<0 0 0 0>, <0 0 0 0>, <0 0 0 0>,
					<0 0 0 0>, <0 0 0 0>, <0 0 0 0>,
					<0 0 0 0>, <0 0 0 0>, <0 0 0 0>,
					<0 0 0 0>, <0 0 0 0>, <0 0 0 0>,
					<0 0 0 0>;
				sprd,chn-config =
					<DISABLE MON_INSIDE MON_WRITE>,
					<DISABLE MON_INSIDE MON_WRITE>,
					<DISABLE MON_INSIDE MON_WRITE>,
					<DISABLE MON_INSIDE MON_WRITE>,
					<DISABLE MON_INSIDE MON_WRITE>,
					<DISABLE MON_INSIDE MON_WRITE>,
					<DISABLE MON_INSIDE MON_WRITE>,
					<DISABLE MON_INSIDE MON_WRITE>,
					<DISABLE MON_INSIDE MON_WRITE>,
					<DISABLE MON_INSIDE MON_WRITE>,
					<DISABLE MON_INSIDE MON_WRITE>,
					<DISABLE MON_INSIDE MON_WRITE>,
					<DISABLE MON_INSIDE MON_WRITE>,
					<DISABLE MON_INSIDE MON_WRITE>,
					<DISABLE MON_INSIDE MON_WRITE>,
					<DISABLE MON_INSIDE MON_WRITE>;
				sprd,id-config =
					<MPUID 0 0xffff>, <MPUID 0 0xffff>,
					<MPUID 0 0xffff>, <MPUID 0 0xffff>,
					<MPUID 0 0xffff>, <MPUID 0 0xffff>,
					<MPUID 0 0xffff>, <MPUID 0 0xffff>,
					<MPUID 0 0xffff>, <MPUID 0 0xffff>,
					<MPUID 0 0xffff>, <MPUID 0 0xffff>,
					<MPUID 0 0xffff>, <MPUID 0 0xffff>,
					<MPUID 0 0xffff>, <MPUID 0 0xffff>;
				sprd,port-map = <0>, <1>, <2>, <3>, <4>,
						<5>, <6>, <7>, <0>, <0>,
						<0>, <0>, <0>, <0>, <0>,
						<0>;
				sprd,ddr-offset = <0x80000000>;
				status = "okay";
			};

			dmc_controller: dmc-controller@60000000  {
				compatible = "sprd,pub-dmc";
				reg = <0x0 0x60000000 0x0 0x9000>,
					<0x0 0x65002000 0x0 0x1000>;
			};

			ptm_trace: ptm@60040000 {
				compatible = "sprd,qogirl6-ptm";
				reg = <0x0 0x60040000 0x0 0x10000>,
					<0x0 0x7c002000 0x0 0x1000>,
					<0x0 0x7c003000 0x0 0x1000>,
					<0x0 0x7c006000 0x0 0x1000>;
				interrupts = <GIC_SPI 109 IRQ_TYPE_LEVEL_HIGH>;
				syscon-names = "enable";
				syscons = <&pub_apb_regs 0x31cc 0x80>;
				clock-names = "clk_cs","cs_src";
				clocks = <&aon_clk CLK_CSSYS>,
					<&pll1 CLK_TWPLL_256M>;
				sprd,funnel-port = <3>;
				sprd,ddr-chn = <8>;
				sprd,chn-name = "CPU", "GPU", "DPU/DCAM",
					"ISP", "AP/VSP/AON", "WTLCP",
					"PUBCP/AUDCP", "WCN";
			};
		};

		aon_apb_regs: syscon@64000000 {
			compatible = "sprd,ums9230-glbregs", "syscon";
			#syscon-cells = <2>;
			reg = <0 0x64000000 0 0x3000>;
		};

		pmu_apb_regs: syscon@64020000 {
			compatible = "sprd,ums9230-glbregs", "syscon";
			#syscon-cells = <2>;
			reg = <0 0x64020000 0 0x3000>;
		};

		ap_intc0_regs: syscon@64300000 {
			compatible = "sprd,ums9230-glbregs", "syscon";
			#syscon-cells = <2>;
			reg = <0 0x64300000 0 0x1000>;
		};

		ap_intc1_regs: syscon@64310000 {
			compatible = "sprd,ums9230-glbregs", "syscon";
			#syscon-cells = <2>;
			reg = <0 0x64310000 0 0x1000>;
		};

		ap_intc2_regs: syscon@64320000 {
			compatible = "sprd,ums9230-glbregs", "syscon";
			#syscon-cells = <2>;
			reg = <0 0x64320000 0 0x1000>;
		};

		ap_intc3_regs: syscon@64330000 {
			compatible = "sprd,ums9230-glbregs", "syscon";
			#syscon-cells = <2>;
			reg = <0 0x64330000 0 0x1000>;
		};

		ap_intc4_regs: syscon@64340000 {
			compatible = "sprd,ums9230-glbregs", "syscon";
			#syscon-cells = <2>;
			reg = <0 0x64340000 0 0x1000>;
		};

		ap_intc5_regs: syscon@64350000 {
			compatible = "sprd,ums9230-glbregs", "syscon";
			#syscon-cells = <2>;
			reg = <0 0x64350000 0 0x1000>;
		};

		anlg_phy_g0_regs: syscon@64550000 {
			compatible = "sprd,ums9230-glbregs", "syscon";
			#syscon-cells = <2>;
			reg = <0 0x64550000 0 0x3000>;
		};

		anlg_phy_g1_regs: syscon@64560000 {
			compatible = "sprd,ums9230-glbregs", "syscon";
			#syscon-cells = <2>;
			reg = <0 0x64560000 0 0x3000>;
		};

		anlg_phy_g2_regs: syscon@64570000 {
			compatible = "sprd,ums9230-glbregs", "syscon";
			#syscon-cells = <2>;
			reg = <0 0x64570000 0 0x3000>;
		};

		anlg_phy_g3_regs: syscon@64580000 {
			compatible = "sprd,ums9230-glbregs", "syscon";
			#syscon-cells = <2>;
			reg = <0 0x64580000 0 0x3000>;
		};

		anlg_phy_gc_regs: syscon@645a0000 {
			compatible = "sprd,ums9230-glbregs", "syscon";
			#syscon-cells = <2>;
			reg = <0 0x645a0000 0 0x3000>;
		};

		anlg_phy_g10_regs: syscon@645b0000 {
			compatible = "sprd,ums9230-glbregs", "syscon";
			#syscon-cells = <2>;
			reg = <0 0x645b0000 0 0x3000>;
		};

		aon {
			compatible = "simple-bus";
			#address-cells = <2>;
			#size-cells = <2>;
			ranges;

			eic_debounce: gpio@64100000 {
				compatible = "sprd,qogirl6-eic-debounce";
				reg = <0 0x64100000 0 0x80>,
				      <0 0x64110000 0 0x80>,
				      <0 0x64120000 0 0x80>,
				      <0 0x64130000 0 0x80>,
				      <0 0x64140000 0 0x80>,
				      <0 0x64150000 0 0x80>;
				gpio-controller;
				#gpio-cells = <2>;
				interrupt-controller;
				#interrupt-cells = <2>;
				interrupts = <GIC_SPI 72 IRQ_TYPE_LEVEL_HIGH>;
			};

			eic_latch: gpio@64100080 {
				compatible = "sprd,qogirl6-eic-latch";
				reg = <0 0x64100080 0 0x20>,
				      <0 0x64110080 0 0x20>,
				      <0 0x64120080 0 0x20>,
				      <0 0x64130080 0 0x20>,
				      <0 0x64140080 0 0x20>,
				      <0 0x64150080 0 0x20>;
				gpio-controller;
				#gpio-cells = <2>;
				interrupt-controller;
				#interrupt-cells = <2>;
				interrupts = <GIC_SPI 72 IRQ_TYPE_LEVEL_HIGH>;
			};

			eic_async: gpio@641000a0 {
				compatible = "sprd,qogirl6-eic-async";
				reg = <0 0x641000a0 0 0x20>,
				      <0 0x641100a0 0 0x20>,
				      <0 0x641200a0 0 0x20>,
				      <0 0x641300a0 0 0x20>,
				      <0 0x641400a0 0 0x20>,
				      <0 0x641500a0 0 0x20>;
				gpio-controller;
				#gpio-cells = <2>;
				interrupt-controller;
				#interrupt-cells = <2>;
				interrupts = <GIC_SPI 72 IRQ_TYPE_LEVEL_HIGH>;
			};

			eic_sync: gpio@641000c0 {
				compatible = "sprd,qogirl6-eic-sync";
				reg = <0 0x641000c0 0 0x20>,
				      <0 0x641100c0 0 0x20>,
				      <0 0x641200c0 0 0x20>,
				      <0 0x641300c0 0 0x20>,
				      <0 0x641400c0 0 0x20>,
				      <0 0x641500c0 0 0x20>;
				gpio-controller;
				#gpio-cells = <2>;
				interrupt-controller;
				#interrupt-cells = <2>;
				interrupts = <GIC_SPI 72 IRQ_TYPE_LEVEL_HIGH>;
			};

			ap_gpio: gpio@641b0000 {
				compatible = "sprd,qogirl6-gpio";
				reg = <0 0x641b0000 0 0x10000>;
				gpio-controller;
				#gpio-cells = <2>;
				interrupt-controller;
				#interrupt-cells = <2>;
				interrupts = <GIC_SPI 61 IRQ_TYPE_LEVEL_HIGH>;
			};

			aon_mailbox: mailbox@641c0000 {
				compatible = "sprd,mailbox";
				reg = <0 0x641c0000 0 0x40000>;
				syscons = <&aon_apb_regs 0x4 0x4>;
				syscon-names = "clk";
				interrupts = <GIC_SPI 82 IRQ_TYPE_LEVEL_HIGH>,
					     <GIC_SPI 83 IRQ_TYPE_LEVEL_HIGH>,
					     <GIC_SPI 84 IRQ_TYPE_LEVEL_HIGH>;
				sprd,sensor = <6>;
				sprd,core-cnt = <9>;
				sprd,version = <0x200>;
			};

			aon_i2c0: i2c@641A0000 {
				compatible = "sprd,qogirl6-hw-i2c";
				reg = <0 0x641A0000 0 0x100>;
				interrupts = <GIC_SPI 68 IRQ_TYPE_LEVEL_HIGH>;
				clock-names = "source", "enable", "i2c",
						"clk_hw_i2c";
				clocks = <&ext_26m>, <&aonapb_gate CLK_I2C_EB>,
					<&aon_clk CLK_AON_I2C>;
				sprd,hw-channels = <5 0x6002>, <7 0x6000>;
				clock-frequency = <400000>;
				#address-cells = <1>;
				#size-cells = <0>;
				status = "disabled";
			};

			ap_thm0: thermal@644B0000 {
				compatible = "sprd,sharkl5-thermal", "sprd,qogirl6-thermal";
				reg = <0 0x644B0000 0 0x10000>;
				clock-names = "enable";
				clocks = <&aonapb_gate CLK_THM0_EB>;
				#thermal-sensor-cells = <1>;
				nvmem-cells = <&thm0_sign>, <&thm0_ratio>;
				nvmem-cell-names = "thm_sign_cal", "thm_ratio_cal";

				cputop0-sensor@0 {
					reg = <0>;
					nvmem-cells = <&thm0_sen0>;
					nvmem-cell-names = "sen_delta_cal";
				};

				ank0-sensor@1 {
					reg = <1>;
					nvmem-cells = <&thm0_sen1>;
					nvmem-cell-names = "sen_delta_cal";
				};

				ank1-sensor@2 {
					reg = <2>;
					nvmem-cells = <&thm0_sen2>;
					nvmem-cell-names = "sen_delta_cal";
				};

				ank2-sensor@3 {
					reg = <3>;
					nvmem-cells = <&thm0_sen3>;
					nvmem-cell-names = "sen_delta_cal";
				};

				prometheus7-sensor@4 {
					reg = <4>;
					nvmem-cells = <&thm0_sen4>;
					nvmem-cell-names = "sen_delta_cal";
				};

				cputop1-sensor@5 {
					reg = <5>;
					nvmem-cells = <&thm0_sen5>;
					nvmem-cell-names = "sen_delta_cal";
				};
			};

			ap_thm2: thermal@644D0000 {
				compatible = "sprd,sharkl5-thermal", "sprd,qogirl6-thermal";
				reg = <0 0x644D0000 0 0x10000>;
				clock-names = "enable";
				clocks = <&aonapb_gate CLK_THM2_EB>;
				#thermal-sensor-cells = <1>;
				nvmem-cells = <&thm2_sign>, <&thm2_ratio>;
				nvmem-cell-names = "thm_sign_cal", "thm_ratio_cal";

				gpu-sensor@0 {
					reg = <0>;
					nvmem-cells = <&thm2_sen0>;
					nvmem-cell-names = "sen_delta_cal";
				};

				ank3-sensor@1 {
					reg = <1>;
					nvmem-cells = <&thm2_sen1>;
					nvmem-cell-names = "sen_delta_cal";
				};

				ank4-sensor@2 {
					reg = <2>;
					nvmem-cells = <&thm2_sen2>;
					nvmem-cell-names = "sen_delta_cal";
				};

				ank5-sensor@3 {
					reg = <3>;
					nvmem-cells = <&thm2_sen3>;
					nvmem-cell-names = "sen_delta_cal";
				};

				prometheus6-sensor@4 {
					reg = <4>;
					nvmem-cells = <&thm2_sen4>;
					nvmem-cell-names = "sen_delta_cal";
				};
			};

			cluster0_sensor: cluster0-sensor@15 {
				compatible = "sprd,cluster0-thermal";
				#thermal-sensor-cells = <1>;
				sensor-names = "ank0-tzone1","ank1-thmzone","ank2-thmzone",
					"ank3-thmzone","ank4-thmzone","ank5-thmzone";
				k-po = <128>;
				k-pu = <256>;
				k-i = <1>;
				k-d = <0>;
				cutoff = <0>;
			};

			cluster1_sensor: cluster1-sensor@16 {
				compatible = "sprd,cluster1-thermal";
				#thermal-sensor-cells = <1>;
				sensor-names = "prometheus6-thmzone", "prometheus7-thmzone";
				k-po = <128>;
				k-pu = <256>;
				k-i = <1>;
				k-d = <0>;
				cutoff = <0>;
			};

			soc_sensor: soc-sensor@17 {
				compatible = "sprd,soc-thermal";
				#thermal-sensor-cells = <1>;
				sensor-names = "cluster0-thmzone","cluster1-thmzone","gpu-thmzone";
				k-po = <164>;
				k-pu = <328>;
				k-i = <2>;
				k-d = <0>;
				cutoff = <0>;
				clear_integral = <3000>;
			};

			adi_bus: spi@64200000 {
				compatible = "sprd,qogirl6-adi",
						"sprd,sharkl5-adi";
				reg = <0 0x64200000 0 0x100000>;
				#address-cells = <1>;
				#size-cells = <0>;
			};

			ap_efuse: efuse@643d0000 {
				status = "okay";
				compatible = "sprd,qogirl6-efuse";
				reg = <0 0x643d0000 0 0x10000>;
				clock-names = "enable";
				hwlocks = <&hwlock 8>;
				clocks = <&aonapb_gate CLK_EFUSE_EB>;
			};

			pwms: pwm@643f0000 {
				compatible = "sprd,qogirl6-pwm", "sprd,sharkl5-pwm";
				reg = <0 0x643f0000 0 0x10000>;
				status = "disabled";
				clock-names = "clk_parent",
					"clk_pwm0", "clk_pwm0_eb",
					"clk_pwm1", "clk_pwm1_eb",
					"clk_pwm2", "clk_pwm2_eb";
				clocks = <&ext_26m>,
					<&aon_clk CLK_PWM0>,
					<&aonapb_gate CLK_PWM0_EB>,
					<&aon_clk CLK_PWM1>,
					<&aonapb_gate CLK_PWM1_EB>,
					<&aon_clk CLK_PWM2>,
					<&aonapb_gate CLK_PWM2_EB>;
				#pwm-cells = <2>;
			};

			topdvfs_controller: topdvfsctrl@64014000 {
				compatible = "sprd,qogirl6-topdvfs", "syscon";
				sprd,syscon-enable = <&aon_apb_regs>;
				module-enable-cfg = <0x4 7>;
				reg = <0 0x64014000 0 0x4000>;
				cpu-dcdc-cells = <&dcdc_cpu0>, <&dcdc_cpu1>;
				device-dcdc-cells = <&dcdc_mm>, <&dcdc_modem>;
				dcdc_cpu0: dcdc-cpu0 {
					dcdc-dvfs-enable = <0x68 20 1>;
					dcdc-judge-vol-sw = <0x68 1 0x7 0>;
					dcdc-subsys-tune-enable = <0x150 6 1>;
					dcdc-supply-mode-cfg = <&dvfs_dcdc_cpu0_supply>;
					syscons = <&pmu_apb_regs REG_PMU_APB_DVFS_BLOCK_SHUTDOWN_CFG MASK_PMU_APB_DCDC_CPU0_DVFS_BLOCK_SHUTDOWN_EN>;
					syscon-names = "dvfs-blk-dcdc-sd";
					dcdc-idle-voltage = <0x16c 3 0x7 6>;
				};
				dcdc_cpu1: dcdc-cpu1 {
					dcdc-dvfs-enable = <0x94 0 1>;
					dcdc-judge-vol-sw = <0x138 18 0x7 0>;
					dcdc-subsys-tune-enable = <0x150 7 1>;
					dcdc-supply-mode-cfg = <&dvfs_dcdc_cpu1_supply>;
					syscons = <&pmu_apb_regs REG_PMU_APB_DVFS_BLOCK_SHUTDOWN_CFG MASK_PMU_APB_DCDC_CPU1_DVFS_BLOCK_SHUTDOWN_EN>;
					syscon-names = "dvfs-blk-dcdc-sd";
					dcdc-idle-voltage = <0x16c 0 0x7 5>;
				};

				dvfs_dcdc_cpu0_supply: dvfs-dcdc-cpu0-supply {
					compatible = "qogirl6-dcdc-cpu0";
				};

				dvfs_dcdc_cpu1_supply: dvfs-dcdc-cpu1-supply {
					compatible = "qogirl6-dcdc-cpu1";
				};

				dcdc_mm: dcdc-mm {
					dcdc-dvfs-enable = <0x18 20 1>;
					dcdc-judge-vol-sw = <0x18 1 0x7 0>;
					dcdc-subsys-cells =	<&audcp_sys>,
								<&gpu_sys>,
								<&mm_sys>;
					audcp_sys: audcp-sys {
						dcdc-subsys-tune-enable = <0x150 5 0>;
					};
					gpu_sys: gpu-sys {
						dcdc-subsys-tune-enable = <0x150 1 1>;
					};

					mm_sys: mm-sys {
						dcdc-subsys-tune-enable = <0x150 2 1>;
					};
				};
				dcdc_modem: dcdc-modem {
					dcdc-dvfs-enable = <0x3c 20 1>;
					dcdc-judge-vol-sw = <0x3c 1 0x7 0>;
					dcdc-subsys-cells =	<&pubcp_sys>,
								<&wtlcp_sys>,
								<&ap_sys>;
					pubcp_sys: pubcp-sys {
						dcdc-subsys-tune-enable = <0x150 4 0>;
					};
					wtlcp_sys: wtlcp-sys {
						dcdc-subsys-tune-enable = <0x150 3 0>;
					};
					ap_sys: ap-sys {
						dcdc-subsys-tune-enable = <0x150 0 0>;
					};
				};
			};

			cpudvfs_dev: cpudvfs-dev@64018000 {
				compatible = "sprd,qogirl6-cpudvfs";
				sprd,syscon-enable = <&aon_apb_regs>;
				module-enable-cfg = <0x4 7>;
				topdvfs-controller = <&topdvfs_controller>;
				reg = <0 0x64018000 0 0x1000>;
				mpll-cells = <&mpll_0>, <&mpll_1>, <&mpll_2>;
				apcpu-dvfs-dcdc-cells = <&apcpu_cpu0>,
							<&apcpu_cpu1>;
				cpudvfs-clusters = <&lit_core_cluster>,
						   <&big_core_cluster>,
						   <&scu_cluster>,
						   <&periph_cluster>,
						   <&gic_cluster>;
				lit_core_cluster: lit-core-cluster {
					cluster-name = "lit-core-cluster";
					row-num = <11>;
					column-num = <7>;
					work-index-cfg = <0x214 0xf>;
					idle-index-cfg = <0x218 0xf>;
					tuning-result-judge = <0>;
					dcdc-name = "DCDC_CPU0";
					map-tbl-regs = <0x60 0x64 0x68 0x6c 0x70 0x74 0x78 0x7c 0x80 0x84 0x88>;
					column-entry-start-bit = <0 2 15 5 9 18 12>;
					column-entry-mask = <0x3 0x7 0x7 0xf 0x7 0x7 0x7>;
					cluster-devices = <&lit_core0_dev>,
							  <&lit_core1_dev>,
							  <&lit_core2_dev>,
							  <&lit_core3_dev>,
							  <&lit_core4_dev>,
							  <&lit_core5_dev>;
					/*sel, div, vol, vote_scu, vote_peri, vote_gic, mpllx*/
					lit-core-dvfs-tbl = <
						0 0 0 0  0 0 0
						1 1 0 1  1 1 0
						2 1 0 2  1 1 0
						3 0 0 3  1 1 0
						3 0 1 4  1 1 1
						1 0 2 5  1 1 0
						3 0 3 6  4 4 2
						2 0 4 7  4 4 0
						3 0 5 8  4 5 3
						3 0 6 9  4 5 4
						3 0 7 10 4 5 5
					>;
					lit_core0_dev:lit-core0-dev {
						device-name = "cpu0";
						sel-get = <0x38 0 3>;
						div-get = <0x38 2 7>;
						vol-get = <0x30 0 7>;
						dfs-idle-disable = <0x1c 0 1>;
					};
					lit_core1_dev:lit-core1-dev {
						device-name = "cpu1";
						sel-get = <0x38 5 3>;
						div-get = <0x38 7 7>;
						vol-get = <0x30 3 7>;
						dfs-idle-disable = <0x1c 1 1>;
					};
					lit_core2_dev:lit-core2-dev {
						device-name = "cpu2";
						sel-get = <0x38 10 3>;
						div-get = <0x38 12 7>;
						vol-get = <0x30 6 7>;
						dfs-idle-disable = <0x1c 2 1>;
					};
					lit_core3_dev:lit-core3-dev {
						device-name = "cpu3";
						sel-get = <0x38 15 3>;
						div-get = <0x38 17 7>;
						vol-get = <0x30 9 7>;
						dfs-idle-disable = <0x1c 3 1>;
					};
					lit_core4_dev:lit-core4-dev {
						device-name = "cpu4";
						sel-get = <0x40 0 3>;
						div-get = <0x40 2 7>;
						vol-get = <0x34 0 7>;
						dfs-idle-disable = <0x1c 8 1>;
					};
					lit_core5_dev:lit-core5-dev {
						device-name = "cpu5";
						sel-get = <0x40 5 3>;
						div-get = <0x40 7 7>;
						vol-get = <0x34 3 7>;
						dfs-idle-disable = <0x1c 9 1>;
					};
				};

				big_core_cluster:big-core-cluster {
					cluster-name = "big-core-cluster";
					row-num = <10>;
					column-num = <7>;
					work-index-cfg = <0x224 0xf>;
					idle-index-cfg = <0x228 0xf>;
					tuning-result-judge = <0>;
					dcdc-name = "DCDC_CPU1";
					map-tbl-regs = <0xa0 0xa4 0xa8 0xac 0xb0 0xb4 0xb8 0xbc 0xc0 0xc4>;
					column-entry-start-bit = <0 2 15 5 9 21 12>;
					column-entry-mask = <0x3 0x7 0x7 0xf 0x7  0x7 0x7>;
					cluster-devices = <&big_core0_dev>,
							  <&big_core1_dev>;
					/*sel, div, vol, vote_scu, vote_peri, vote_gic, mpllx*/
					big-core-dvfs-tbl = <
						0 0 0 0  0 0 0
						2 1 0 2  1 1 0
						3 0 0 4  1 1 0
						1 0 1 4  1 1 0
						3 0 2 6  4 4 1
						2 0 3 7  4 4 0
						3 0 4 8  4 5 3
						3 0 5 10 4 5 4
						3 0 6 10 4 5 5
						3 0 7 10 4 5 7
					>;
					big_core0_dev: big-core0-dev {
						device-name = "cpu6";
						sel-get = <0x40 10 3>;
						div-get = <0x40 12 7>;
						vol-get = <0x34 6 7>;
						dfs-idle-disable = <0x1c 10 1>;
					};
					big_core1_dev: big-core1-dev {
						device-name = "cpu7";
						sel-get = <0x40 15 3>;
						div-get = <0x40 17 7>;
						vol-get = <0x34 9 7>;
						dfs-idle-disable = <0x1c 11 1>;
					};
				};

				scu_cluster: scu-cluster {
					cluster-name = "scu-cluster";
					row-num = <11>;
					column-num = <5>;
					work-index-cfg = <0x22C 0xf>;
					idle-index-cfg = <0x230 0xf>;
					dcdc-name = "DCDC_CPU0";
					tuning-func-cfg = <0x18 1>;
					map-tbl-regs = <0x180 0x184 0x188 0x18c 0x190 0x194 0x198 0x19c 0x1a0 0x1a4 0x1a8>;
					column-entry-start-bit = <0 2 11 5 8>;
					column-entry-mask = <0x3 0x7 0x7 0x7 0x7>;
					cluster-devices = <&scu_dev>, <&ace_dev>;
					/* sel div vol ace_div mpllx */
					scu-dvfs-tbl = <
						0 0 0 0 0
						3 0 0 1 0
						2 1 0 1 0
						3 0 0 1 1
						1 0 1 1 0
						3 0 2 1 2
						3 0 3 1 3
						2 0 4 1 0
						3 0 5 1 4
						3 0 6 1 5
						3 0 7 1 6
					>;
					scu_dev: scu-dev {
						device-name = "scu";
						sel-get = <0x38 20 3>;
						div-get = <0x38 22 7>;
						vol-get = <0x30 12 7>;
						dfs-idle-disable = <0x1c 4 1>;
					};
					ace_dev: ace-dev {
						device-name = "ace";
						sel-get = <0x38 20 3>;
						div-get = <0x38 25 7>;
						vol-get = <0x30 12 7>;
					};
				};

				periph_cluster:periph-cluster {
					cluster-name = "periph-cluster";
					row-num = <6>;
					column-num = <3>;
					work-index-cfg = <0x23C 0x7>;
					idle-index-cfg = <0x240 0x7>;
					dcdc-name = "DCDC_CPU0";
					tuning-func-cfg = <0x18 0>;
					map-tbl-regs = <0x1f4 0x1f8 0x1fc 0x200 0x204 0x208>;
					column-entry-start-bit = <0 2 5>;
					column-entry-mask = <0x3 0x7 0x7>;
					cluster-devices = <&periph_dev>;
					/* sel div vol */
					periph-dvfs-tbl = <
						0 0 0
						1 0 0
						2 1 2
						3 1 2
						2 0 2
						3 0 6
					>;
					periph_dev: periph-dev {
						device-name = "periph";
						sel-get = <0x3C 0 3>;
						div-get = <0x3C 2 7>;
						vol-get = <0x30 18 7>;
						dfs-idle-disable = <0x1c 6 1>;
					};
				};

				gic_cluster: gic-cluster {
					cluster-name = "gic-cluster";
					row-num = <6>;
					column-num = <3>;
					work-index-cfg = <0x2e0 0x7>;
					idle-index-cfg = <0x2e4 0x7>;
					dcdc-name = "DCDC_CPU0";
					tuning-func-cfg = <0x18 2>;
					map-tbl-regs = <0x280 0x284 0x288 0x28c 0x290 0x294>;
					column-entry-start-bit = <0 2 5>;
					column-entry-mask = <0x3 0x7 0x7>;
					cluster-devices = <&gic_dev>;
					/*sel div vol*/
					gic-dvfs-tbl = <
						0 0 0
						1 0 0
						2 1 2
						3 1 2
						2 0 2
						3 0 2
					>;
					gic_dev: gic-dev {
						device-name = "gic";
						sel-get = <0x3c 12 3>;
						div-get = <0x3c 14 7>;
						vol-get = <0x30 21 7>;
						dfs-idle-disable = <0x1c 7 1>;
					};
				};

				mpll_0: mpll-ananke {
					sprd,syscon-ang = <&anlg_phy_gc_regs>;
					mpll-rst = <0xc8 4 6 7>;
					relock-cfg = <0x244 1>;
					pd-cfg = <0x244 0>;
				};

				mpll_1: mpll-prometheus {
					sprd,syscon-ang = <&anlg_phy_g3_regs>;
					mpll-rst = <0x98 4 6 7>;
					relock-cfg = <0x258 1>;
					pd-cfg = <0x258 0>;
				};

				mpll_2: mpll-scu {
					sprd,syscon-ang = <&anlg_phy_gc_regs>;
					mpll-rst = <0x10c 3 5 6>;
					relock-cfg = <0x26c 1>;
					pd-cfg = <0x26c 0>;
				};

				apcpu_cpu0: apcpu-cpu0 {
					subsys-dcdc-vol-sw = <0x20 4 0x7 6>;
					subsys-dvfs-state = <0x44 0 7>;
				};
				apcpu_cpu1: apcpu-cpu1 {
					subsys-dcdc-vol-sw = <0x24 4 0x7 5>;
					subsys-dvfs-state = <0x4c 0 7>;
				};
			};

			aon_systimer: timer@64450000 {
				compatible = "sprd,syst-timer";
				reg = <0 0x64450000 0 0x10>;
			};

			aon_sysfrt: timer@64460000 {
				compatible = "sprd,sysfrt-timer";
				reg = <0 0x64460000 0 0x10>;
				clocks = <&ext_32k>;
			};

			timer@64470000 {
				compatible = "sprd,qogirl6-timer",
						"sprd,sc9860-timer";
				reg = <0 0x64470000 0 0x20>;
				interrupts = <GIC_SPI 71 IRQ_TYPE_LEVEL_HIGH>;
				clocks = <&ext_32k>;
			};

			timer@64470020 {
				compatible = "sprd,qogirl6-suspend-timer",
						"sprd,sc9860-suspend-timer";
				reg = <0 0x64470020 0 0x20>;
				clocks = <&ext_32k>;
			};

			watchdog@644e0000 {
				compatible = "sprd,wdt-r2p0-fiq";
				reg = <0 0x644e0000 0 0x10000>;
				interrupts = <GIC_SPI 79 IRQ_TYPE_LEVEL_HIGH>;
				timeout-sec = <12>;
				clock-names = "enable", "rtc_enable";
				clocks = <&aonapb_gate CLK_APCPU_WDG_EB>,
				       <&aonapb_gate CLK_AC_WDG_RTC_EB>;
			};

			pin_controller: pinctrl@64710000 {
				compatible = "sprd,qogirl6-pinctrl";
				reg = <0 0x64710000 0 0x10000>;
				vbc_iis3_0: vbc-iis3-0 {
					pins = "QOGIRL6_IIS_INF0_SYS_SEL";
					sprd,control = <0xe>;
				};

				vbc_iism0_0: vbc-iism0-0 {
					pins = "QOGIRL6_IIS_INF0_SYS_SEL";
					sprd,control = <0x10>;
				};

				vbc_iis_to_pad: vbc-iis-to-pad {
					pins = "QOGIRL6_VBC_IIS_INF_SYS_SEL";
					sprd,control = <0x0>;
				};

				vbc_iis_to_aon_usb: vbc-iis-to-aon-usb {
					pins = "QOGIRL6_VBC_IIS_INF_SYS_SEL";
					sprd,control = <0x1>;
				};

				audcp_iis0_1: audcp_iis0_1 {
					pins = "QOGIRL6_IIS_INF1_SYS_SEL";
					sprd,control = <0x7>;
				};

				audcp_iis1_1: audcp_iis1_1 {
					pins = "QOGIRL6_IIS_INF1_SYS_SEL";
					sprd,control = <0x8>;
				};

				vbc_iism0_1: vbc-iism0-1 {
					pins = "QOGIRL6_IIS_INF1_SYS_SEL";
					sprd,control = <0x10>;
				};

				vbc_iism0_3: vbc-iism0-3 {
					pins = "QOGIRL6_IIS_INF3_SYS_SEL";
					sprd,control = <0x10>;
				};

				vbc_iis0_3: vbc-iis0-3 {
					pins = "QOGIRL6_IIS_INF3_SYS_SEL";
					sprd,control = <0xb>;
				};

				vbc_iis1_3: vbc-iis1-3 {
					pins = "QOGIRL6_IIS_INF3_SYS_SEL";
					sprd,control = <0xc>;
				};

				vbc_iis2_3: vbc-iis2-3 {
					pins = "QOGIRL6_IIS_INF3_SYS_SEL";
					sprd,control = <0xd>;
				};

				vbc_iis3_3: vbc-iis3-3 {
					pins = "QOGIRL6_IIS_INF3_SYS_SEL";
					sprd,control = <0xe>;
				};

				ap_iis0_3: ap-iis0-3 {
					pins = "QOGIRL6_IIS_INF3_SYS_SEL";
					sprd,control = <0x0>;
				};
				vbc_iis3_5: vbc-iis3-5 {
					pins = "QOGIRL6_IIS_INF5_SYS_SEL";
					sprd,control = <0x0>;
				};

				uart_inf_sel0: ap-uart1-9 {
					pins = "QOGIRL6_UART_INF9_SYS_SEL";
					sprd,control = <0x1>;
				};

				uart_inf_sel1: auddsp-uart0-1 {
					pins = "QOGIRL6_UART_INF1_SYS_SEL";
					sprd,control = <0x8>;
				};
			};

			djtag: djtag@64740000 {
				compatible = "sprd,djtag";
				status = "okay";
				reg = <0 0x64740000 0 0x1000>;
				syscon-names = "soft_rst";
				syscons = <&aon_apb_regs REG_AON_APB_APB_RST3
					MASK_AON_APB_DJTAG_SOFT_RST>;
				clock-names = "enable", "tck";
				clocks = <&aonapb_gate CLK_DJTAG_EB>,
					<&aonapb_gate CLK_DJTAG_TCK_EB>;
				hwlocks = <&hwlock 10>;
				hwlock-names = "djtag";

				#address-cells = <1>;
				#size-cells = <0>;

				aon-busmonitor@8{
					compatible = "sprd,qogirl6-busmonitor", "sprd,sharkl5pro-busmonitor";
					interrupts = <GIC_SPI 81 IRQ_TYPE_LEVEL_HIGH>;
					reg = <0x8>;
					sprd,bm-num = <7>;
					sprd,bm-name =
						"AP", "WTLCP", "AUDCP", "PUBCP",
						"USBOTG", "CM4", "WCN";
					sprd,bm-type =
						<AXI>, <AXI>, <AXI>, <AXI>,
						<AXI>, <AXI>, <AXI>;
					sprd,bm-dap = <0>, <1>, <2>, <3>,
						<4>, <5>, <8>;
					sprd,bm-config =
						<DISABLE MON_WRITE MON_INSIDE>,
						<DISABLE MON_WRITE MON_INSIDE>,
						<DISABLE MON_WRITE MON_INSIDE>,
						<DISABLE MON_WRITE MON_INSIDE>,
						<DISABLE MON_WRITE MON_INSIDE>,
						<DISABLE MON_WRITE MON_INSIDE>,
						<DISABLE MON_WRITE MON_INSIDE>;
					sprd,bm-id =
						<DISABLE 0 AXIID>,
						<DISABLE 0 AXIID>,
						<DISABLE 0 AXIID>,
						<DISABLE 0 AXIID>,
						<DISABLE 0 AXIID>,
						<DISABLE 0 AXIID>,
						<DISABLE 0 AXIID>;
					sprd,bm-ranges =
						<0 0>,
						<0 0>,
						<0 0>,
						<0 0>,
						<0 0>,
						<0 0>,
						<0 0>;
				};
			};

			usb: usb@64900000 {
				compatible = "sprd,qogirl6-musb";
				reg = <0 0x64900000 0 0x2000>;
				interrupts = <GIC_SPI 69 IRQ_TYPE_LEVEL_HIGH>;
				interrupt-names = "mc";
				clocks = <&aonapb_gate CLK_OTG_UTMI_EB>;
				clock-names = "core_clk";
				usb-phy = <&hsphy>;
				phy-names = "usb";
				dr-mode = "peripheral";
				multipoint = "true";
				wakeup-source;
			};

			sfp: sfp-unisoc {
				compatible = "sprd,sfp";
				sprd,enable-pamwifi = <0>;
			};

			modem_dbg_log: modem-dbg-log@64750000 {
				compatible = "sprd,dbg-log-qogirl6";
				reg = <0 0x64750000 0 0x4000>;
				sprd,syscon-mm-ahb = <&mm_ahb_regs>;
				sprd,syscon-dsi-apb = <&anlg_phy_g10_regs>;
				sprd,ch-name = "TRAINING", "WTL", "MADR", "TPIU", "DBUS", "WCN";
				sprd,ch-index = <15 1 0 2 3 4>;
				sprd,dcfix;
				sprd,mm;
				status = "disabled";
			};

			hwlock: hwspinlock@64910000 {
				compatible = "sprd,hwspinlock-r3p0";
				reg = <0 0x64910000 0 0x10000>;
				#hwlock-cells = <1>;
				clock-names = "enable";
				clocks = <&aonapb_gate CLK_SPLK_EB>;
			};

			hsphy: hsphy@64570000 {
				compatible = "sprd,qogirl6-phy";
				reg = <0 0x64570000 0 0x3030>;
				reg-names = "phy_glb_regs";
				sprd,syscon-enable = <&aon_apb_regs>;
				sprd,syscon-anag2 = <&anlg_phy_g2_regs>;
				sprd,vdd-voltage = <3300000>;
				/* HS03 code for P211026-03673 by gaochao at 20211028 start */
				io-channels = <&pmic_adc 30>, <&pmic_adc 31>;
				io-channel-names = "dp", "dm";
				/* HS03 code for P211026-03673 by gaochao at 20211028 end */
				#phy-cells = <0>;
			};

			usbpinmux: usbpinmux {
				compatible = "sprd,qogirl6-usbpinmux";
				sprd,syscon-config = <&aon_apb_regs>;
				syscons = <&aon_apb_regs REG_AON_APB_USB_UART_JTAG_MUX
					(MASK_AON_APB_USB_JTAG_HW_SEL_EN |
					MASK_AON_APB_DAP_USB_JTAG_SEL |
					MASK_AON_APB_USB_BYPASS_SEL | MASK_AON_APB_UART_JTAG_SEL)>;
				syscon-names = "usb_uart_jtag_mux";
				vdd-supply = <&vddusb33>;
				sprd,vdd-voltage = <3300000>;
				pinctrl-names = "uart_inf_sel0", "uart_inf_sel1";
				pintcrl-0 = <&uart_inf_sel0>;
				pintcrl-1 = <&uart_inf_sel1>;
			};
		};

		agcp {
			compatible = "simple-bus";
			#address-cells = <2>;
			#size-cells = <2>;
			ranges;

			vbc_v4: vbc@56480000 {
				compatible = "sprd,qogirl6-vbc";
				#sound-dai-cells = <1>;
				reg = <0 0x56480000 0 0x1000>;
				sprd,syscon-agcp-ahb = <&audcp_ahb_regs>;
				sprd,vbc-phy-offset = <0x0>;    /*no offset*/
				/*pinctrl*/
				pinctrl-names =
				"vbc_iis3_0", "vbc_iism0_0", "vbc_iis_to_pad",
				"vbc_iis_to_aon_usb", "vbc_iism0_1", "vbc_iism0_3",
				"vbc_iis0_3", "vbc_iis1_3", "vbc_iis2_3",
				"vbc_iis3_3", "ap_iis0_3", "vbc_iis3_5",
				"audcp_iis0_1";
				pinctrl-0 = <&vbc_iis3_0>;
				pinctrl-1 = <&vbc_iism0_0>;
				pinctrl-2 = <&vbc_iis_to_pad>;
				pinctrl-3 = <&vbc_iis_to_aon_usb>;
				pinctrl-4 = <&vbc_iism0_1>;
				pinctrl-5 = <&vbc_iism0_3>;
				pinctrl-6 = <&vbc_iis0_3>;
				pinctrl-7 = <&vbc_iis1_3>;
				pinctrl-8 = <&vbc_iis2_3>;
				pinctrl-9 = <&vbc_iis3_3>;
				pinctrl-10 = <&ap_iis0_3>;
				pinctrl-11 = <&vbc_iis3_5>;
				pinctrl-12 = <&audcp_iis0_1>;
				pinctrl-13 = <&audcp_iis1_1>;
			};

			pdm_dmic: pdm-dmic@56401000 {
				compatible = "sprd,pdm";
				status = "disabled";
				reg = <0 0x56401000 0 0x1000>;
				#sound-dai-cells = <1>;
				sprd,syscon-agcp-ahb = <&audcp_ahb_regs>;
			};

			mcdt@56490000{
				compatible = "sprd,mcdt-r2p0";
				reg = <0 0x56490000 0 0x170>;
				interrupts = <GIC_SPI 182 IRQ_TYPE_LEVEL_HIGH>;
				sprd,ap-addr-offset = <0x0>;
				sprd,syscon-agcp-ahb = <&audcp_ahb_regs>;
			};

			agcp_dma: dma-controller@56580000 {
				compatible = "sprd,qogirl6-dma";
				reg = <0 0x56580000 0 0x4000>;
				interrupts = <GIC_SPI 180 IRQ_TYPE_LEVEL_HIGH>;
				#dma-cells = <1>;
				#dma-channels = <32>;
				clock-names = "enable", "ashb_eb";
				clocks = <&audcpahb_gate CLK_AUDCP_DMA_AP_EB>,
					<&audcpahb_gate CLK_AUDCP_DMA_AP_ASHB_EB>;
			};

			sprd_audio_codec_dig: audio-codec@56750000 {
				compatible = "sprd,audio-codec-dig-agcp";
				reg = <0 0x56750000 0 0x1000>;
				sprd,syscon-agcp-ahb = <&audcp_ahb_regs>;
			};

			agdsp-access {
				compatible = "sprd,agdsp-access";
				sprd,syscon-agcp-ahb = <&aon_apb_regs>;
				sprd,syscon-pmu-apb = <&pmu_apb_regs>;
				syscons = <&pmu_apb_regs REG_PMU_APB_DEEP_SLEEP_MON_0
					MASK_PMU_APB_AUDCP_DEEP_SLEEP>,
					<&pmu_apb_regs REG_PMU_APB_SLEEP_STATUS_0
					MASK_PMU_APB_AUDCP_SLP_STATUS>,
					<&pmu_apb_regs REG_PMU_APB_PWR_STATUS_DBG_21
					MASK_PMU_APB_PD_AUDCP_STATE>,
					<&pmu_apb_regs REG_PMU_APB_PWR_STATUS_DBG_21
					MASK_PMU_APB_PD_AUDCP_AUDDSP_STATE>,
					<&aon_apb_regs REG_AON_APB_AUDCP_CTRL
					MASK_AON_APB_AP_2_AUD_ACCESS_EN>;
				syscon-names = "audcp_pmu_sleep_ctrl",
						"audcp_pmu_slp_status",
						"audcp_pmu_pwr_status4",
						"audcp_pmu_pwr_status3",
						"ap_access_ena";
				sprd,dst = <5>;
				sprd,channel = <130>;
				sprd,sipc-name = "sipc0";
				sprd,mailbox-core = <5>; /* AGDSP id */
				sprd,ddr-addr-offset = <0x0>;
				hwlocks = <&hwlock 11>;
				sprd,auto_agcp_access = <0>;
			};
		};
	};

	sprd_pcm: sprd-pcm-audio {
		compatible = "sprd,qogirl6-pcm-platform";
		#sound-dai-cells = <0>;
		/* agcp dma_ap */
		dmas = <&agcp_dma 1 &agcp_dma 2
			&agcp_dma 3 &agcp_dma 4
			&agcp_dma 5 &agcp_dma 6
			&agcp_dma 7 &agcp_dma 8
			&agcp_dma 9 &agcp_dma 10
			&agcp_dma 11 &agcp_dma 12
			&agcp_dma 13 &agcp_dma 14
			&agcp_dma 15 &agcp_dma 16
			&agcp_dma 9 &agcp_dma 9
			&agcp_dma 11 &agcp_dma 14
			&agcp_dma 19 &agcp_dma 20>;

		dma-names =
			"normal_p_l", "normal_p_r",
			"normal_c_l", "normal_c_r",
			"normal23_p_l", "normal23_p_r",
			"normal23_c_l", "normal23_c_r",
			"dspcap_c", "a2dppcm_p",
			"voice_c","fast_p",
			"loop_c", "loop_p",
			"voip_c", "voip_p",
			/* dspfmcap_c and dspbtscocap_c same as dspcap_c */
			"dspfmcap_c", "dspbtscocap_c",
			/* recognise_c same as voice_c, voice_pcm_p same as loop_p */
			"recognise_c", "voice_pcm_p",
			"hifi_p", "hifi_fast_p";
	};

	sprd_compr: sprd-compr-audio {
		compatible = "sprd,qogirl6-compress-platform";
		#sound-dai-cells = <0>;
		dmas = <&agcp_dma 17 &agcp_dma 18>;
		dma-names = "compr_dma_stage0", "compr_dma_stage1";
	};

	sprd_fe_dai: sprd-fe-dai {
		compatible = "sprd,fe-dai";
		#sound-dai-cells = <1>;
	};

	sprd_route_pcm: sprd-routing-pcm {
		compatible = "sprd,pcm-routing";
		#sound-dai-cells = <0>;
	};

	audio-sipc{
		compatible = "sprd,audio_sipc";
		sprd,mailbox-core = <5>;  /* AGDSP id */
	};

	audio-mem-mgr {
		compatible = "sprd,audio-mem-sharkl5", "sprd,audio-mem-sharkl5pro";
		/*
		 * base is 0x94100000 for ums9230
		 * 1. reserved ddr layout total 3M:
		 * 2M (ap used. include dma data,dma node(dynamic),
		 * dsp log(65K), dsp pcm(65K)) + 1k(cmd param) 2K + 16b(cmd) +
		 * 1K AUDIO_STRUCT_PARA + 1K(nxp/cvs) + dsp used(4k)) +
		 * 0.5M dsp memdump
		 */
		ddr32-ap-dsp-map-offset = <0x0>;
		/*
		 * 2M for dynamic alloc, 0x94100000 - 0x94300000 ddr32-dma,
		 * 1M for other
		 */
		sprd,ddr32-dma = <0x94100000 0x200000>;
		/* 512K,  0x94300000 - 0x94380000*/
		sprd,ddr32-dspmemdump = <0x94300000 0x80000>;
		/* 1K cmd para, 0x94380000 - 0x94380400 */
		sprd,cmdaddr = <0x94380000 0x400>;
		/* 2K + 16byte,0x94380400 - 0x94380e10 */
		sprd,smsg-addr = <0x94380400 0xa10>;
		/* 1K AUDIO_STRUCT_PARA 0x94380e10 - 0x94381210*/
		sprd,shmaddr-aud-str = <0x94380e10 0x400>;
		/* 5K DSP_VBC_PARA, 0x94381210 - 0x94382610 */
		sprd,shmaddr-dsp-vbc = <0x94381210 0x1400>;
		/* 1K nxp/cvs para, 0x94382610 - 0x94382a10 */
		sprd,shmaddr-nxp = <0x94382610 0x400>;
		/* 2K ivsence smartpa param, 0x94382a10 - 0x94383a10 */
		sprd,shmaddr-dsp-smartpa = <0x94382a10 0x1000>;
		/* 1K REG DUMP, 0x94383a10 - 0x94383e10 */
		sprd,shmaddr-reg-dump = <0x94383a10 0x400>;

		/* 2. iram layout total 32K */
		sprd,iram-ap-base =  <0x56800000>;
		sprd,iram-dsp-base = <0x56800000>;
		/* mp3 23K */
		sprd,offload-addr = <0x56800000 0x5c00>;
		/* 0.5 reserved */
		/* normal capture total 8.5K */
		/* 0x200 (0.5K) */
		sprd,normal-captue-linklilst-node1 =<0x56805e00 0x200>;
		/*
		 * normal capture data
		 * 7.5K
		 * pagesize(4K) aligned
		 */
		sprd,normal-captue-data =<0x56806000 0x1e00>;
		/* 0x200(0.5K) */
		sprd,normal-captue-linklilst-node2 =<0x56807e00 0x200>;
		/* audcp aon iram */
		sprd,audcp-aon-iram = <0x65009400 0x1000>;
	};

	audio-dsp-dump@0 {/* audio dsp log */
		compatible = "sprd,audio-dsp-log";
		sprd-usemem-type =<0x5>;
		sprd-dst = /bits/ 8 <1>; /* AGDSP */
		sprd-channel =/bits/ 8 <4>;
		sprd-rxblocknum=<0x8>;
		sprd-rxblocksize=<0x2000>;
	};

	audio-dsp-dump@1 {/* audio dsp pcm */
		compatible = "sprd,audio-dsp-pcm";
		sprd-usemem-type =<0x5>;
		sprd-dst = /bits/ 8 <1>; /* AGDSP */
		sprd-channel =/bits/ 8 <3>;
		sprd-rxblocknum=<0x8>;
		sprd-rxblocksize=<0x2000>;
	};

	audio-dsp-dump@2 {/* audio dsp log */
		compatible = "sprd,audio-dsp-mem";
		sprd-usemem-type =<0x9>;
		sprd-usemem-bytes =<0x80000>;
		sprd-dst = /bits/ 8 <1>; /* AGDSP */
		sprd-channel =/bits/ 8 <5>;
		/* for cmd para addr */
		sprd,dspdumpmem = <0x56200000 0x10000
				   0x65009400 0x1000
				   0x89300000 0x5f000>;
	};

	audio_pipe_voice {
		compatible = "sprd,audio_pipe_voice";
		sprd,writesync = <0>;
		sprd,maxuserwritebufsize = <0>;
		sprd,channel = <2>;
	};

	audio_pipe_effect {
		compatible = "sprd,audio_pipe_effect";
		sprd,writesync = <1>;
		sprd,maxuserwritebufsize = <1024>;
		sprd,channel = <8>;
	};

	audio_pipe_voiceproc {
		compatible = "sprd,audio_pipe_recordproc";
		sprd,writesync = <1>;
		sprd,maxuserwritebufsize = <1024>;
		sprd,channel = <9>;
	};

	audio_pipe_bthal {
		compatible = "sprd,audio_pipe_bthal";
		sprd,writesync = <0>;
		sprd,maxuserwritebufsize = <0>;
		sprd,channel = <11>;
	};

	audiocp-dvfs {
		compatible = "sprd,qogirl6-audcp-dvfs";
		sprd,channel = <10>;
	};

	audiocp_boot {
		compatible = "sprd,audcp-boot";
		dsp-reboot-mode = <1>;
		syscons = <&pmu_apb_regs REG_PMU_APB_PD_AUDCP_CFG_0 0x3000000>,
			<&pmu_apb_regs REG_PMU_APB_PD_AUDCP_AUDDSP_CFG_0 0x3000000>,
			<&pmu_apb_regs REG_PMU_APB_FORCE_DEEP_SLEEP_CFG_0 MASK_PMU_APB_AUDCP_FORCE_DEEP_SLEEP_REG>,
			<&pmu_apb_regs REG_PMU_APB_DM_SOFT_RST  MASK_PMU_APB_AUDCP_SOFT_RST>,
			<&pmu_apb_regs REG_PMU_APB_SYS_SOFT_RST_0  MASK_PMU_APB_AUDCP_SOFT_RST>,
			<&pmu_apb_regs REG_PMU_APB_SOFT_RST_SEL_0 MASK_PMU_APB_AUDCP_SOFT_RST>,
			<&pmu_apb_regs REG_PMU_APB_PWR_STATUS_DBG_21  MASK_PMU_APB_PD_AUDCP_STATE>,
			<&pmu_apb_regs REG_PMU_APB_PWR_STATUS_DBG_21 MASK_PMU_APB_PD_AUDCP_AUDDSP_STATE >,
			<&pmu_apb_regs REG_AON_APB_AUTO_GATE_CTRL1 MASK_WTL_AON_APB_RSV_REG_B_ZEROS>,
			<&aon_apb_regs REG_AON_APB_AUDCP_BOOT_PROT MASK_AON_APB_AUDCP_REG_PROT_VAL>,
			<&aon_apb_regs REG_AON_APB_AUDCP_DSP_CTRL0 MASK_WTL_AON_APB_RSV_REG_B_ZEROS>,
			<&aon_apb_regs REG_AON_APB_AUDCP_DSP_CTRL1 MASK_AON_APB_AUDCP_DSP_BOOT>;
		syscon-names = "sysshutdown", "coreshutdown", "deepsleep", "corereset",
			"sysreset", "reset_sel", "sysstatus", "corestatus", "sleepstatus",
			"bootprotect", "bootvector", "bootaddress_sel";
	};

	apipe-pcm {
		compatible = "sprd,apipe";
	};

	apipe-cmd-in {
		compatible = "sprd,apipe";
	};

	apipe-cmd-out {
		compatible = "sprd,apipe";
	};

	ext_26m: ext-26m {
		compatible = "fixed-clock";
		#clock-cells = <0>;
		clock-frequency = <26000000>;
		clock-output-names = "ext-26m";
	};

	ext_32k: ext-32k {
		compatible = "fixed-clock";
		#clock-cells = <0>;
		clock-frequency = <32768>;
		clock-output-names = "ext-32k";
	};

	rco_100m: rco-100m {
		compatible = "fixed-clock";
		#clock-cells = <0>;
		clock-frequency = <100000000>;
		clock-output-names = "rco-100m";
	};

	dphy_250m: dphy-250m {
		compatible = "fixed-clock";
		#clock-cells = <0>;
		clock-frequency = <250000000>;
		clock-output-names = "dphy-250m";
	};

	dphy_333m3: dphy-333m3 {
		compatible = "fixed-clock";
		#clock-cells = <0>;
		clock-frequency = <333300000>;
		clock-output-names = "dphy-333m3";
	};

	cache_efuse: efuse@65014c00 {
		compatible = "sprd,sharkl5-cache-efuse", "sprd,qogirl6-cache-efuse";
		#address-cells = <1>;
		#size-cells = <1>;
		reg = <0 0x65014c00 0 0x3ff>;

		uid_start: uid-start@5c{
			reg = <0x5c 0x4>;
		};

		uid_end: uid-end@58{
			reg = <0x58 0x4>;
		};

		thm0_sign: thm0-sign@38 {
			reg = <0x38 0x1>;
			bits = <0 1>;
		};

		thm0_ratio: thm0-ratio@38 {
			reg = <0x38 0x1>;
			bits = <1 7>;
		};

		thm0_sen0: thm0-sen0@39 {
			reg = <0x39 0x1>;
			bits = <0 8>;
		};

		thm0_sen1: thm0-sen1@41 {
			reg = <0x41 0x1>;
			bits = <0 8>;
		};

		thm0_sen2: thm0-sen2@40 {
			reg = <0x40 0x1>;
			bits = <0 8>;
		};

		thm0_sen3: thm0-sen3@43 {
			reg = <0x43 0x1>;
			bits = <0 8>;
		};

		thm0_sen4: thm0-sen4@42 {
			reg = <0x42 0x1>;
			bits = <0 8>;
		};

		thm0_sen5: thm0-sen5@2f {
			reg = <0x2f 0x1>;
			bits = <0 8>;
		};

		thm2_sign: thm2-sign@3e {
			reg = <0x3e 0x4>;
			bits = <0 1>;
		};

		thm2_ratio: thm2-ratio@3e {
			reg = <0x3e 0x4>;
			bits = <1 7>;
		};

		thm2_sen0: thm2-sen0@3f {
			reg = <0x3f 0x4>;
			bits = <0 8>;
		};

		thm2_sen1: thm2-sen1@2e {
			reg = <0x2e 0x4>;
			bits = <0 8>;
		};

		thm2_sen2: thm2-sen2@29 {
			reg = <0x29 0x4>;
			bits = <0 8>;
		};

		thm2_sen3: thm2-sen3@28 {
			reg = <0x28 0x4>;
			bits = <0 8>;
		};

		thm2_sen4: thm2-sen4@2b {
			reg = <0x2b 0x4>;
			bits = <0 8>;
		};
		wcn_alpha: wcn-alpha@81 {
			reg = <0x24 0x4>;
		};

		gpu_bin: gpu-bin@1b{
			reg = <0x1b 0x4>;
			bits = <3 3>;
		};

		dvfs_bin_dsu: dvfs-bin-dsu@13 {
			reg = <0x13 0x4>;
			bits = <0 3>;
		};

		dvfs_bin_cpu0: dvfs-bin-cpu0@17 {
			reg = <0x17 0x4>;
			bits = <0 3>;
		};

		dvfs_bin_cpu1: dvfs-bin-cpu1@1b {
			reg = <0x1b 0x4>;
			bits = <0 3>;
		};
	};

	input_booster {
		status = "okay";
		compatible = "input_booster";
		resValcount = "2";
		max_resource_count = "2";
		max_cluster_count = "2";
		#address-cells = <1>;
		#size-cells = <0>;

		/* Each Cpu Cluster Start Cpu */
		cpu_cluster_policy = "6,0";

		/* < CPU, DDR > */
		ib_release_values = "-1, 16";

		/* Select Allowed Resource Index Group */
		allowed_resources = "0,1";

		booster_key@1 {
			input_booster,label = "key";
			input_booster,type = <0>;	/* BOOSTER_DEVICE_KEY */

			/* Time table */
			input_booster,head_time = <200>;
			input_booster,tail_time = <0>;

			/* Resource Table Sequentially identified with index
			 * CPU's ID & Index : 0
			 * DDR's ID & Index : 1
			*/

			/* Input Booster Resource Frequency */
			inputbooster,resource {
				compatible = "resource";
				resource@1 {
					resource,label = "CPU";
					resource,value = <1274000 0>;
				};

				resource@2 {
					resource,label = "DDR";
					resource,value = <0 0>;
				};
			};
		};

		booster_key@2 {
			input_booster,label = "touchkey";
			input_booster,type = <1>;	/* BOOSTER_DEVICE_TOUCHKEY */

			/* Time table */
			input_booster,head_time = <1>;
			input_booster,tail_time = <300>;

			/* Input Booster Resource Frequency */
			inputbooster,resource {
				compatible = "resource";
				resource@1 {
					resource,label = "CPU";
					resource,value = <0 1042000>;
				};

				resource@2 {
					resource,label = "DDR";
					resource,value = <0 0>;
				};
			};
		};

		booster_key@3 {
			input_booster,label = "touch";
			input_booster,type = <2>;	/* BOOSTER_DEVICE_TOUCH */

			/* Time table */
			input_booster,head_time = <130>;
			input_booster,tail_time = <500>;

			/* Input Booster Resource Frequency */
			inputbooster,resource {
				compatible = "resource";
				resource@1 {
					resource,label = "CPU";
					resource,value = <1274000 1042000>;
				};

				resource@2 {
					resource,label = "DDR";
					resource,value = <1333 1333>;
				};
			};
		};

		booster_key@4 {
			input_booster,label = "multitouch";
			input_booster,type = <3>;	/* BOOSTER_DEVICE_MULTITOUCH */

			/* Time table */
			input_booster,head_time = <1000>;
			input_booster,tail_time = <500>;

			/* Input Booster Resource Frequency */
			inputbooster,resource {
				compatible = "resource";
				resource@1 {
					resource,label = "CPU";
					resource,value = <1534000 1274000>;
				};

				resource@2 {
					resource,label = "DDR";
					resource,value = <0 0>;
				};
			};
		};

		booster_key@5 {
			input_booster,label = "keyboard";
			input_booster,type = <4>;	/* BOOSTER_DEVICE_KEYBOARD */

			/* Time table */
			input_booster,head_time = <130>;
			input_booster,tail_time = <130>;

			/* Input Booster Resource Frequency */
			inputbooster,resource {
				compatible = "resource";
				resource@1 {
					resource,label = "CPU";
					resource,value = <1042000 1042000>;
				};

				resource@2 {
					resource,label = "DDR";
					resource,value = <0 0>;
				};
			};
		};

		booster_key@6 {
			input_booster,label = "mouse";
			input_booster,type = <5>;	/* BOOSTER_DEVICE_MOUSE */

			/* Time table */
			input_booster,head_time = <200>;
			input_booster,tail_time = <300>;

			/* Input Booster Resource Frequency */
			inputbooster,resource {
				compatible = "resource";
				resource@1 {
					resource,label = "CPU";
					resource,value = <1274000 1042000>;
				};

				resource@2 {
					resource,label = "DDR";
					resource,value = <0 0>;
				};
			};
		};

		booster_key@7 {
			input_booster,label = "mouse_wheel";
			input_booster,type = <6>;	/* BOOSTER_DEVICE_MOUSE */

			/* Time table */
			input_booster,head_time = <200>;
			input_booster,tail_time = <0>;

			/* Input Booster Resource Frequency */
			inputbooster,resource {
				compatible = "resource";
				resource@1 {
					resource,label = "CPU";
					resource,value = <1274000 0>;
				};

				resource@2 {
					resource,label = "DDR";
					resource,value = <0 0>;
				};
			};
		};

		booster_key@8 {
			input_booster,label = "pen_hover";
			input_booster,type = <7>;	/* BOOSTER_DEVICE_MOUSE */

			/* Time table */
			input_booster,head_time = <200>;
			input_booster,tail_time = <300>;

			/* Input Booster Resource Frequency */
			inputbooster,resource {
				compatible = "resource";
				resource@1 {
					resource,label = "CPU";
					resource,value = <1274000 1042000>;
				};

				resource@2 {
					resource,label = "DDR";
					resource,value = <0 0>;
				};
			};
		};

		booster_key@9 {
			input_booster,label = "pen";
			input_booster,type = <8>;	/* BOOSTER_DEVICE_MOUSE */

			/* Time table */
			input_booster,head_time = <200>;
			input_booster,tail_time = <600>;

			/* Input Booster Resource Frequency */
			inputbooster,resource {
				compatible = "resource";
				resource@1 {
					resource,label = "CPU";
					resource,value = <1719000 1042000>;
				};

				resource@2 {
					resource,label = "DDR";
					resource,value = <0 0>;
				};
			};
		};
		/* If you need to add new key type, add it this position */
	};
};
